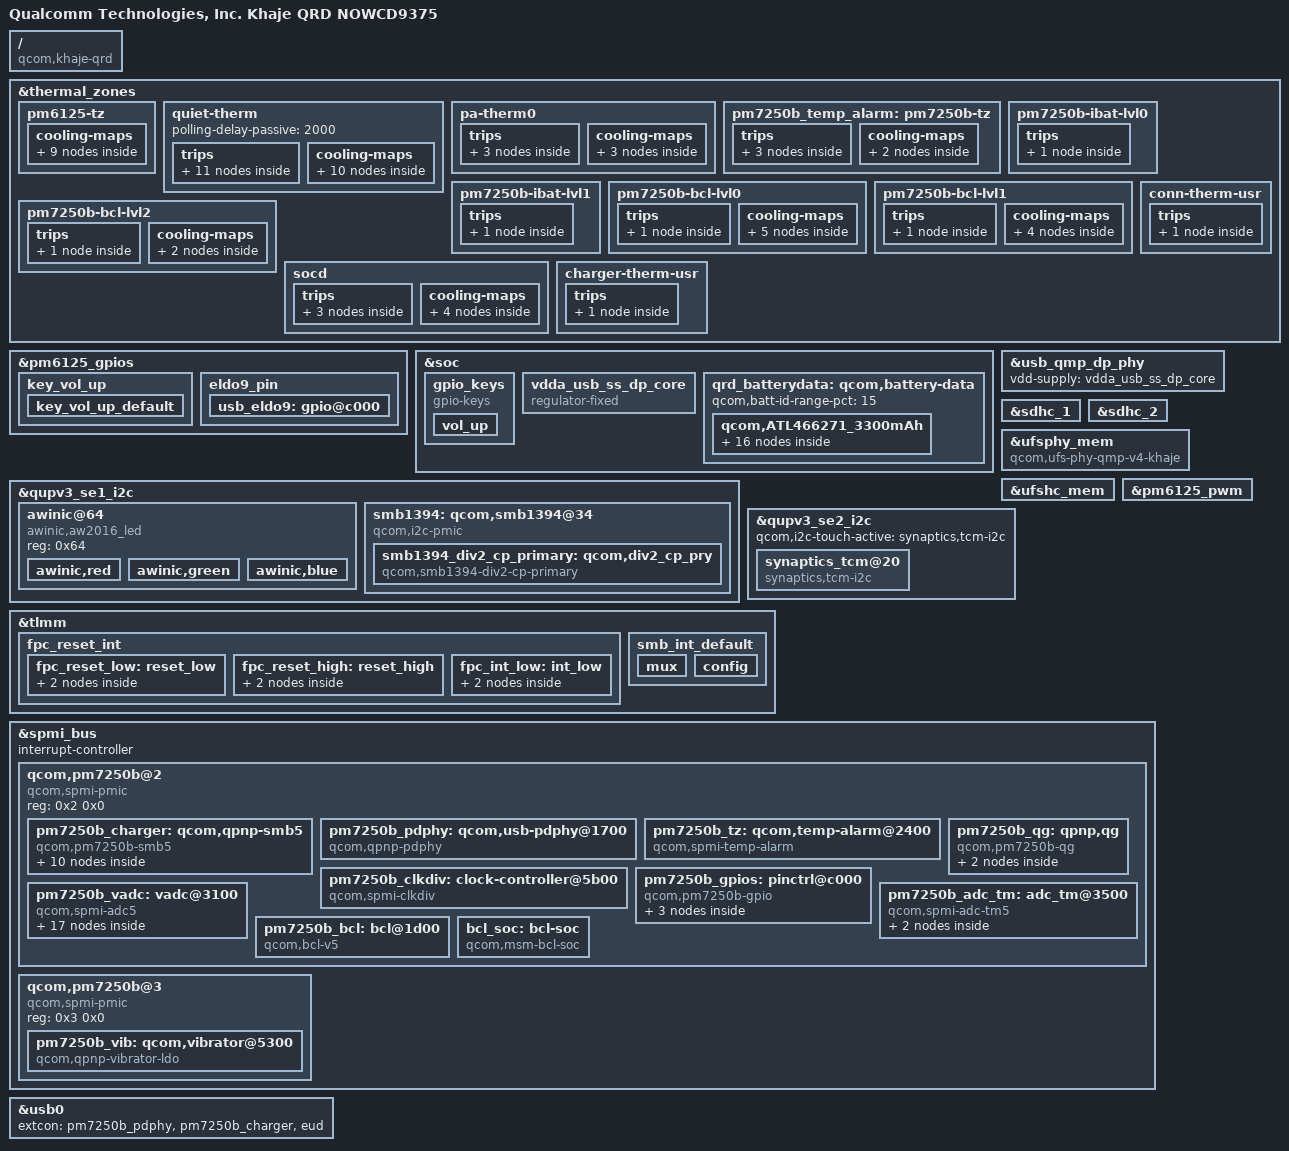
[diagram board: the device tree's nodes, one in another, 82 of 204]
// SPDX-License-Identifier: GPL-2.0-only
/*
 * Stock dtbo.img entry 14: Qualcomm Technologies, Inc. Khaje QRD NOWCD9375
 * Kernel board overlay part, reconstructed from the stock image
 * (Qualcomm reference board as built in the Xiaomi sapphire tree).
 */

/dts-v1/;
/plugin/;

/ {
	model = "Qualcomm Technologies, Inc. Khaje QRD NOWCD9375";
	compatible = "qcom,khaje-qrd", "qcom,khaje", "qcom,qrd";
	qcom,msm-id = <0x24a 0x10000>;
	qcom,board-id = <0x2010b 0x0>;
	qcom,pmic-id = <0x2d 0x2e 0x0 0x0>;
};

#include <dt-bindings/clock/qcom,gcc-khaje.h>
#include <dt-bindings/clock/qcom,rpmcc.h>

&thermal_zones {
	pm6125-tz {
		cooling-maps {
			trip0_cpu0 {
				trip = <&pm6125_trip0>;
				cooling-device = <&CPU0 7 7>;
			};

			trip0_cpu4 {
				trip = <&pm6125_trip0>;
				cooling-device = <&CPU4 6 0xffffffff>;
			};

			trip1_cpu1 {
				trip = <&pm6125_trip1>;
				cooling-device = <&cpu1_pause 1 1>;
			};

			trip1_cpu2 {
				trip = <&pm6125_trip1>;
				cooling-device = <&cpu2_pause 1 1>;
			};

			trip1_cpu3 {
				trip = <&pm6125_trip1>;
				cooling-device = <&cpu3_pause 1 1>;
			};

			trip1_cpu4 {
				trip = <&pm6125_trip1>;
				cooling-device = <&cpu4_pause 1 1>;
			};

			trip1_cpu5 {
				trip = <&pm6125_trip1>;
				cooling-device = <&cpu5_pause 1 1>;
			};

			trip1_cpu6 {
				trip = <&pm6125_trip1>;
				cooling-device = <&cpu6_pause 1 1>;
			};

			trip1_cpu7 {
				trip = <&pm6125_trip1>;
				cooling-device = <&cpu7_pause 1 1>;
			};
		};
	};
};

&pm6125_gpios {
	key_vol_up {
		key_vol_up_default: key_vol_up_default {
			pins = "gpio5";
			function = "normal";
			input-enable;
			bias-pull-up;
			power-source = <0>;
		};
	};

	eldo9_pin {
		usb_eldo9: gpio@c000 {
			pins = "gpio1";
			function = "normal";
			qcom,drive-strength = <2>;
			power-source = <0>;
			bias-disable;
			output-high;
		};
	};
};

&soc {
	gpio_keys {
		compatible = "gpio-keys";
		label = "gpio-keys";
		pinctrl-names = "default";
		pinctrl-0 = <&key_vol_up_default>;

		vol_up {
			label = "volume_up";
			gpios = <&pm6125_gpios 5 1>;
			linux,input-type = <1>;
			linux,code = <115>;
			linux,can-disable;
			debounce-interval = <15>;
			gpio-key,wakeup;
		};
	};

	vdda_usb_ss_dp_core: vdda_usb_ss_dp_core {
		compatible = "regulator-fixed";
		regulator-name = "vdd_supply";
		regulator-min-microvolt = <880000>;
		regulator-max-microvolt = <880000>;
		enable-active-high;
		gpio = <&pm6125_gpios 1 0>;
		pinctrl-names = "default";
		pinctrl-0 = <&usb_eldo9>;
	};
};

&usb_qmp_dp_phy {
	vdd-supply = <&vdda_usb_ss_dp_core>;
};

&qupv3_se1_i2c {
	awinic@64 {
		compatible = "awinic,aw2016_led";
		reg = <0x64>;

		awinic,red {
			awinic,name = "red";
			awinic,id = <0>;
			awinic,imax = <2>;
			awinic,led-current = <3>;
			awinic,max-brightness = <255>;
			awinic,rise-time-ms = <6>;
			awinic,hold-time-ms = <0>;
			awinic,fall-time-ms = <6>;
			awinic,off-time-ms = <4>;
		};

		awinic,green {
			awinic,name = "green";
			awinic,id = <1>;
			awinic,imax = <2>;
			awinic,led-current = <3>;
			awinic,max-brightness = <255>;
			awinic,rise-time-ms = <6>;
			awinic,hold-time-ms = <0>;
			awinic,fall-time-ms = <6>;
			awinic,off-time-ms = <4>;
		};

		awinic,blue {
			awinic,name = "blue";
			awinic,id = <2>;
			awinic,imax = <2>;
			awinic,led-current = <3>;
			awinic,max-brightness = <255>;
			awinic,rise-time-ms = <6>;
			awinic,hold-time-ms = <0>;
			awinic,fall-time-ms = <6>;
			awinic,off-time-ms = <4>;
		};
	};
};

&sdhc_1 {
	vdd-supply = <&L24A>;
	qcom,vdd-voltage-level = <2960000 2960000>;
	qcom,vdd-current-level = <0 570000>;
	vdd-io-supply = <&L11A>;
	qcom,vdd-io-always-on;
	qcom,vdd-io-lpm-sup;
	qcom,vdd-io-voltage-level = <1800000 1800000>;
	qcom,vdd-io-current-level = <0 325000>;
	pinctrl-names = "default", "sleep";
	pinctrl-0 = <&sdc1_on>;
	pinctrl-1 = <&sdc1_off>;
	status = "ok";
};

&sdhc_2 {
	vdd-supply = <&L22A>;
	qcom,vdd-voltage-level = <2960000 2960000>;
	qcom,vdd-current-level = <0 800000>;
	vdd-io-supply = <&L5A>;
	qcom,vdd-io-voltage-level = <1800000 2960000>;
	qcom,vdd-io-current-level = <0 22000>;
	vdd-io-bias-supply = <&L7A>;
	qcom,vdd-io-bias-voltage-level = <1256000 1256000>;
	qcom,vdd-io-bias-current-level = <0 6000>;
	pinctrl-names = "default", "sleep";
	pinctrl-0 = <&sdc2_on>;
	pinctrl-1 = <&sdc2_off>;
	cd-gpios = <&tlmm 88 1>;
	status = "ok";
};

&ufsphy_mem {
	compatible = "qcom,ufs-phy-qmp-v4-khaje";
	vdda-phy-supply = <&L4A>;
	vdda-pll-supply = <&L18A>;
	vdda-phy-max-microamp = <85700>;
	vdda-pll-max-microamp = <18300>;
	status = "ok";
};

&ufshc_mem {
	vdd-hba-supply = <&gcc_ufs_phy_gdsc>;
	vdd-hba-fixed-regulator;
	vcc-supply = <&L24A>;
	vcc-max-microamp = <800000>;
	vccq2-supply = <&L11A>;
	vccq2-max-microamp = <800000>;
	qcom,vddp-ref-clk-supply = <&L18A>;
	qcom,vddp-ref-clk-max-microamp = <100>;
	reset-gpios = <&tlmm 113 1>;
	resets = <&gcc GCC_UFS_PHY_BCR>;
	reset-names = "rst";
	status = "ok";
};

&pm6125_pwm {
	status = "ok";
};

&qupv3_se2_i2c {
	status = "okay";
	qcom,i2c-touch-active = "synaptics,tcm-i2c";

	synaptics_tcm@20 {
		compatible = "synaptics,tcm-i2c";
		reg = <0x20>;
		interrupt-parent = <&tlmm>;
		interrupts = <80 8200>;
		pinctrl-names = "pmx_ts_active", "pmx_ts_suspend", "pmx_ts_release";
		pinctrl-0 = <&ts_int_active &ts_reset_active>;
		pinctrl-1 = <&ts_int_suspend &ts_reset_suspend>;
		pinctrl-2 = <&ts_release>;
		synaptics,irq-gpio = <&tlmm 80 8200>;
		synaptics,irq-on-state = <0>;
		synaptics,reset-gpio = <&tlmm 86 0>;
		synaptics,reset-on-state = <0>;
		synaptics,reset-active-ms = <20>;
		synaptics,reset-delay-ms = <200>;
		synaptics,power-delay-ms = <200>;
		synaptics,ubl-i2c-addr = <0x20>;
		synaptics,extend_report;
		synaptics,firmware-name = "synaptics_firmware_k.img";
	};
};

&thermal_zones {
	quiet-therm {
		polling-delay-passive = <2000>;

		trips {
			quiet_batt_trip0: batt-trip0 {
				temperature = <41000>;
				hysteresis = <2000>;
				type = "passive";
			};

			quiet_modem_trip0: modem-trip0 {
				temperature = <42000>;
				hysteresis = <2000>;
				type = "passive";
			};

			quiet_batt_trip1: batt-trip1 {
				temperature = <43000>;
				hysteresis = <2000>;
				type = "passive";
			};

			quiet_batt_trip2: batt-trip2 {
				temperature = <45000>;
				hysteresis = <2000>;
				type = "passive";
			};

			quiet_gold_trip: gold-trip {
				temperature = <47000>;
				hysteresis = <0>;
				type = "passive";
			};

			quiet_batt_trip3: batt-trip3 {
				temperature = <47000>;
				hysteresis = <2000>;
				type = "passive";
			};

			quiet_batt_trip4: batt-trip4 {
				temperature = <48000>;
				hysteresis = <1000>;
				type = "passive";
			};

			quiet_gpu_trip: gpu-trip {
				temperature = <48000>;
				hysteresis = <4000>;
				type = "passive";
			};

			quiet_silver_trip: silver-trip {
				temperature = <50000>;
				hysteresis = <0>;
				type = "passive";
			};

			quiet_hvx_trip: hvx-trip {
				temperature = <52000>;
				hysteresis = <4000>;
				type = "passive";
			};

			quiet_modem_trip1: modem-trip1 {
				temperature = <60000>;
				hysteresis = <4000>;
				type = "passive";
			};
		};

		cooling-maps {
			gold_cdev {
				trip = <&quiet_gold_trip>;
				cooling-device = <&CPU4 0 4>;
			};

			silver_cdev {
				trip = <&quiet_silver_trip>;
				cooling-device = <&CPU0 0 2>;
			};

			gpu_cdev {
				trip = <&quiet_gpu_trip>;
				cooling-device = <&msm_gpu 0 3>;
			};

			hvx_cdev {
				trip = <&quiet_hvx_trip>;
				cooling-device = <&cdsp_sw 4 4>;
			};

			mdm_cdev0 {
				trip = <&quiet_modem_trip0>;
				cooling-device = <&modem_proc 1 1>;
			};

			mdm_cdev1 {
				trip = <&quiet_modem_trip1>;
				cooling-device = <&modem_proc 3 3>;
			};
		};
	};

	pa-therm0 {
		trips {
			pa_therm0_trip0: pa-therm0-trip0 {
				temperature = <52000>;
				hysteresis = <2000>;
				type = "passive";
			};

			pa_therm0_trip1: pa-therm0-trip1 {
				temperature = <54000>;
				hysteresis = <2000>;
				type = "passive";
			};

			pa_therm0_trip2: pa-therm0-trip2 {
				temperature = <60000>;
				hysteresis = <4000>;
				type = "passive";
			};
		};

		cooling-maps {
			modem_cdev0 {
				trip = <&pa_therm0_trip0>;
				cooling-device = <&modem_pa 1 1>;
			};

			modem_cdev1 {
				trip = <&pa_therm0_trip1>;
				cooling-device = <&modem_pa 2 2>;
			};

			modem_cdev2 {
				trip = <&pa_therm0_trip2>;
				cooling-device = <&modem_pa 3 3>;
			};
		};
	};
};

&tlmm {
	fpc_reset_int: fpc_reset_int {
		fpc_reset_low: reset_low {
			mux {
				pins = "gpio104";
				function = "gpio";
			};

			config {
				pins = "gpio104";
				drive-strength = <2>;
				bias-disable;
				output-low;
			};
		};

		fpc_reset_high: reset_high {
			mux {
				pins = "gpio104";
				function = "gpio";
			};

			config {
				pins = "gpio104";
				drive-strength = <2>;
				bias-disable;
				output-high;
			};
		};

		fpc_int_low: int_low {
			mux {
				pins = "gpio97";
				function = "gpio";
			};

			config {
				pins = "gpio97";
				drive-strength = <2>;
				bias-pull-down;
				input-enable;
			};
		};
	};
};

&spmi_bus {
	#address-cells = <2>;
	#size-cells = <0>;
	interrupt-controller;
	#interrupt-cells = <4>;

	qcom,pm7250b@2 {
		compatible = "qcom,spmi-pmic";
		reg = <0x2 0x0>;
		#address-cells = <1>;
		#size-cells = <0>;

		pm7250b_charger: qcom,qpnp-smb5 {
			compatible = "qcom,pm7250b-smb5";
			depends-on-supply = <&pm7250b_vadc>;
			#address-cells = <1>;
			#size-cells = <1>;
			#cooling-cells = <2>;
			qcom,thermal-mitigation = <8000000 7500000 7000000 6500000 6000000 5500000 5000000 4500000
			                           4000000 3500000 3000000 2500000 2000000 1500000 1000000 500000>;
			qcom,hvdcp2-max-icl-ua = <2000000>;
			qcom,hvdcp2-12v-max-icl-ua = <1500000>;
			status = "ok";
			#io-channel-cells = <1>;
			io-channels = <&pm7250b_vadc 8 &pm7250b_vadc 7
			               &pm7250b_vadc 9 &pm7250b_vadc 6
			               &pm7250b_vadc 79 &pm7250b_vadc 153
			               &pm7250b_vadc 131 &pm7250b_vadc 77
			               &pm7250b_qg 75 &pm7250b_qg 70
			               &pm7250b_qg 69 &pm7250b_qg 66
			               &pm7250b_qg 71 &pm7250b_qg 93
			               &pm7250b_qg 78 &pm7250b_qg 68
			               &pm7250b_qg 91 &pm7250b_qg 72
			               &pm7250b_qg 45 &pm7250b_qg 83
			               &pm7250b_qg 73 &pm7250b_qg 82
			               &pm7250b_qg 84 &pm7250b_qg 86>;
			io-channel-names = "usb_in_voltage", "usb_in_current", "chg_temp", "die_temp", "conn_temp", "sbux_res", "vph_voltage", "skin_temp", "resistance_id", "voltage_now", "temp", "capacity", "voltage_ocv", "voltage_avg", "debug_battery", "real_capacity", "cc_soc", "current_now", "voltage_max", "charge_full", "charge_counter", "cycle_count", "charge_full_design", "time_to_full_now";
			qcom,battery-data = <&qrd_batterydata>;
			qcom,sec-charger-config = <1>;
			qcom,auto-recharge-soc = <98>;
			qcom,step-charging-enable;
			qcom,sw-jeita-enable;
			qcom,charger-temp-max = <800>;
			qcom,smb-temp-max = <800>;
			qcom,suspend-input-on-debug-batt;
			qcom,fcc-stepping-enable;
			qcom,fcc-step-delay-ms = <100>;
			qcom,fcc-step-size-ua = <100000>;
			qcom,smb-internal-pull-kohm = <0>;
			dpdm-supply = <&usb2_phy0>;

			qcom,chgr@1000 {
				reg = <0x1000>;
				interrupts = <2 16 0 1 2 16 1 1
				              2 16 2 1 2 16 3 1
				              2 16 4 1 2 16 5 1
				              2 16 6 1 2 16 7 1>;
				interrupt-names = "chgr-error", "chg-state-change", "step-chg-state-change", "step-chg-soc-update-fail", "step-chg-soc-update-req", "fg-fvcal-qualified", "vph-alarm", "vph-drop-prechg";
			};

			qcom,dcdc@1100 {
				reg = <0x1100>;
				interrupts = <2 17 0 1 2 17 1 1
				              2 17 2 1 2 17 3 3
				              2 17 4 3 2 17 5 3
				              2 17 6 1 2 17 7 3>;
				interrupt-names = "otg-fail", "otg-oc-disable-sw", "otg-oc-hiccup", "bsm-active", "high-duty-cycle", "input-current-limiting", "concurrent-mode-disable", "switcher-power-ok";
			};

			qcom,batif@1200 {
				reg = <0x1200>;
				interrupts = <2 18 0 1 2 18 2 3
				              2 18 3 3 2 18 4 3
				              2 18 5 3 2 18 6 3
				              2 18 7 3>;
				interrupt-names = "bat-temp", "bat-ov", "bat-low", "bat-therm-or-id-missing", "bat-terminal-missing", "buck-oc", "vph-ov";
			};

			qcom,usb@1300 {
				reg = <0x1300>;
				interrupts = <2 19 0 3 2 19 1 3
				              2 19 2 3 2 19 3 3
				              2 19 4 3 2 19 5 3
				              2 19 6 1 2 19 7 1>;
				interrupt-names = "usbin-collapse", "usbin-vashdn", "usbin-uv", "usbin-ov", "usbin-plugin", "usbin-revi-change", "usbin-src-change", "usbin-icl-change";
			};

			qcom,dc@1400 {
				reg = <0x1400>;
				interrupts = <2 20 1 3 2 20 2 3
				              2 20 3 3 2 20 4 3
				              2 20 5 3 2 20 6 1
				              2 20 7 1>;
				interrupt-names = "dcin-vashdn", "dcin-uv", "dcin-ov", "dcin-plugin", "dcin-revi", "dcin-pon", "dcin-en";
			};

			qcom,typec@1500 {
				reg = <0x1500>;
				interrupts = <2 21 0 1 2 21 1 1
				              2 21 2 1 2 21 3 1
				              2 21 4 1 2 21 5 1
				              2 21 6 1 2 21 7 1>;
				interrupt-names = "typec-or-rid-detect-change", "typec-vpd-detect", "typec-cc-state-change", "typec-vconn-oc", "typec-vbus-change", "typec-attach-detach", "typec-legacy-cable-detect", "typec-try-snk-src-detect";
			};

			qcom,misc@1600 {
				reg = <0x1600>;
				interrupts = <2 22 0 1 2 22 1 1
				              2 22 2 1 2 22 3 1
				              2 22 4 3 2 22 5 1
				              2 22 6 1 2 22 7 1>;
				interrupt-names = "wdog-snarl", "wdog-bark", "aicl-fail", "aicl-done", "smb-en", "imp-trigger", "temp-change", "temp-change-smb";
			};

			qcom,chg-sdam@b000 {
				reg = <0xb000>;
			};

			smb5_vbus: qcom,smb5-vbus {
				regulator-name = "smb5-vbus";
			};

			smb5_vconn: qcom,smb5-vconn {
				regulator-name = "smb5-vconn";
			};
		};

		pm7250b_pdphy: qcom,usb-pdphy@1700 {
			compatible = "qcom,qpnp-pdphy";
			reg = <0x1700>;
			interrupts = <2 23 0 1 2 23 1 1
			              2 23 2 1 2 23 3 1
			              2 23 4 1 2 23 5 1
			              2 23 6 1 2 23 7 1>;
			interrupt-names = "sig-tx", "sig-rx", "msg-tx", "msg-rx", "msg-tx-failed", "msg-tx-discarded", "msg-rx-discarded", "fr-swap";
			#io-channel-cells = <1>;
			qcom,default-sink-caps = <5000 3000 9000 3000 12000 2250>;
			vdd-pdphy-supply = <&L15A>;
			vbus-supply = <&smb5_vbus>;
			vconn-supply = <&smb5_vconn>;
			io-channels = <&pm7250b_charger 4 &pm7250b_charger 3
			               &pm7250b_charger 13 &pm7250b_charger 2
			               &pm7250b_charger 31 &pm7250b_charger 29
			               &pm7250b_charger 30 &pm7250b_charger 0
			               &pm7250b_charger 32 &pm7250b_charger 12
			               &pm7250b_charger 11 &pm7250b_charger 10
			               &pm7250b_charger 1 &pm7250b_charger 7>;
			io-channel-names = "pd_active", "typec_cc_orientation", "connector_type", "typec_power_role", "pd_usb_suspend_supported", "typec_src_rp", "pd_in_hard_reset", "pr_current_max", "pr_swap", "pd_voltage_min", "pd_voltage_max", "real_type", "typec_mode", "pe_start";
		};

		pm7250b_tz: qcom,temp-alarm@2400 {
			compatible = "qcom,spmi-temp-alarm";
			reg = <0x2400>;
			interrupts = <2 36 0 3>;
			io-channels = <&pm7250b_vadc 6>;
			io-channel-names = "thermal";
			#thermal-sensor-cells = <0>;
			qcom,temperature-threshold-set = <1>;
		};

		pm7250b_qg: qpnp,qg {
			compatible = "qcom,pm7250b-qg";
			depends-on-supply = <&pm6125_rtc>;
			#address-cells = <1>;
			#size-cells = <1>;
			qcom,vbatt-cutoff-mv = <3400>;
			qcom,vbatt-low-mv = <3500>;
			qcom,vbatt-low-cold-mv = <3800>;
			qcom,vbatt-empty-mv = <3200>;
			qcom,vbatt-empty-cold-mv = <3100>;
			qcom,s3-entry-fifo-length = <2>;
			qcom,soc_decimal_rate = <0 32 10 30 20 28 30 28
			                         40 28 50 28 60 28 70 28
			                         80 28 90 26 95 10 99 5>;
			status = "ok";
			#io-channel-cells = <1>;
			io-channels = <&pm7250b_vadc 42 &pm7250b_vadc 75
			               &pm7250b_charger 55 &pm7250b_charger 63
			               &pm7250b_charger 64 &pm7250b_charger 57>;
			io-channel-names = "batt-therm", "batt-id", "input_current_limited", "recharge_soc", "force_recharge", "charge_done";
			qcom,qg-iterm-ma = <150>;
			qcom,hold-soc-while-full;
			qcom,linearize-soc;
			qcom,cl-feedback-on;
			qcom,tcss-enable;
			qcom,fvss-enable;
			qcom,fvss-vbatt-mv = <3500>;
			qcom,bass-enable;
			qcom,use-cp-iin-sns;

			qcom,qgauge@4800 {
				status = "okay";
				reg = <0x4800>;
				interrupts = <2 72 0 3 2 72 1 3
				              2 72 2 1 2 72 3 1
				              2 72 4 1>;
				interrupt-names = "qg-batt-missing", "qg-vbat-low", "qg-vbat-empty", "qg-fifo-done", "qg-good-ocv";
			};

			qcom,qg-sdam@b100 {
				status = "okay";
				reg = <0xb100>;
			};
		};

		pm7250b_clkdiv: clock-controller@5b00 {
			compatible = "qcom,spmi-clkdiv";
			reg = <0x5b00>;
			#clock-cells = <1>;
			qcom,num-clkdivs = <1>;
			clock-output-names = "pm7250b_div_clk1";
			clocks = <&rpmcc RPM_PXO_CLK>;
			clock-names = "xo";
			assigned-clocks = <&pm7250b_clkdiv 1>;
			assigned-clock-rates = <19200000>;
		};

		pm7250b_gpios: pinctrl@c000 {
			compatible = "qcom,pm7250b-gpio";
			reg = <0xc000>;
			gpio-controller;
			#gpio-cells = <2>;
			interrupt-controller;
			#interrupt-cells = <2>;

			disp_lcd_bias_en {
				disp_lcd_bias_en_default: disp_lcd_bias_en_default {
					pins = "gpio5";
					function = "func1";
					input-disable;
					output-enable;
					bias-disable;
					power-source = <0>;
					qcom,drive-strength = <2>;
				};
			};

			pm7250b_smb_int_default: pm7250b_smb_int_default {
				pins = "gpio6";
				function = "gpio";
				input-enable;
				bias-pull-up;
				qcom,pull-up-strength = <0>;
				power-source = <0>;
			};
		};

		pm7250b_vadc: vadc@3100 {
			compatible = "qcom,spmi-adc5";
			reg = <0x3100>;
			reg-names = "adc5-usr-base";
			#address-cells = <1>;
			#size-cells = <0>;
			interrupts = <2 49 0 1>;
			interrupt-names = "eoc-int-en-set";
			qcom,adc-vdd-reference = <1875>;
			#io-channel-cells = <1>;
			io-channel-ranges;

			ref_gnd@0 {
				reg = <0x0>;
				label = "ref_gnd";
				qcom,pre-scaling = <1 1>;
			};

			vref_1p25@1 {
				reg = <0x1>;
				label = "vref_1p25";
				qcom,pre-scaling = <1 1>;
			};

			die_temp@2 {
				reg = <0x6>;
				label = "die_temp";
				qcom,pre-scaling = <1 1>;
			};

			vph_pwr@83 {
				reg = <0x83>;
				label = "vph_pwr";
				qcom,pre-scaling = <1 3>;
			};

			vbat_sns@84 {
				reg = <0x84>;
				label = "vbat_sns";
				qcom,pre-scaling = <1 3>;
			};

			usb_in_i_uv@7 {
				reg = <0x7>;
				label = "usb_in_i_uv";
				qcom,pre-scaling = <1 1>;
			};

			usb_in_v_div_16@8 {
				reg = <0x8>;
				label = "usb_in_v_div_16";
				qcom,pre-scaling = <1 16>;
			};

			chg_temp@9 {
				reg = <0x9>;
				label = "chg_temp";
				qcom,pre-scaling = <1 1>;
			};

			bat_therm@4a {
				reg = <0x4a>;
				label = "bat_therm";
				qcom,ratiometric;
				qcom,hw-settle-time = <200>;
				qcom,pre-scaling = <1 1>;
			};

			bat_therm_30k@2a {
				reg = <0x2a>;
				label = "bat_therm_30k";
				qcom,ratiometric;
				qcom,hw-settle-time = <200>;
				qcom,pre-scaling = <1 1>;
			};

			bat_therm_400k@6a {
				reg = <0x6a>;
				label = "bat_therm_400k";
				qcom,ratiometric;
				qcom,hw-settle-time = <200>;
				qcom,pre-scaling = <1 1>;
			};

			bat_id@4b {
				reg = <0x4b>;
				label = "bat_id";
				qcom,ratiometric;
				qcom,hw-settle-time = <200>;
				qcom,pre-scaling = <1 1>;
			};

			smb1390_therm@e {
				reg = <0xe>;
				label = "smb1390_therm";
				qcom,hw-settle-time = <200>;
				qcom,pre-scaling = <1 1>;
				qcom,scale-fn-type = <16>;
			};

			chg_sbux@99 {
				reg = <0x99>;
				label = "chg_sbux";
				qcom,pre-scaling = <1 3>;
			};

			mid_chg_div6@1e {
				reg = <0x1e>;
				label = "chg_mid";
				qcom,pre-scaling = <1 6>;
			};

			charger_skin_therm@4d {
				reg = <0x4d>;
				label = "charger_skin_therm";
				qcom,ratiometric;
				qcom,hw-settle-time = <200>;
				qcom,pre-scaling = <1 1>;
			};

			conn_therm@4f {
				reg = <0x4f>;
				label = "conn_therm";
				qcom,ratiometric;
				qcom,hw-settle-time = <200>;
				qcom,pre-scaling = <1 1>;
			};
		};

		pm7250b_adc_tm: adc_tm@3500 {
			compatible = "qcom,spmi-adc-tm5";
			reg = <0x3500>;
			interrupts = <2 53 0 1>;
			interrupt-names = "pm-adc-tm5";
			#address-cells = <1>;
			#size-cells = <0>;
			#thermal-sensor-cells = <1>;
			status = "ok";

			charger_skin_therm@4d {
				reg = <0x0>;
				io-channels = <&pm7250b_vadc 77>;
				qcom,ratiometric;
				qcom,hw-settle-time-us = <200>;
			};

			conn_therm@4f {
				reg = <0x1>;
				io-channels = <&pm7250b_vadc 79>;
				qcom,ratiometric;
				qcom,hw-settle-time-us = <200>;
			};
		};

		pm7250b_bcl: bcl@1d00 {
			compatible = "qcom,bcl-v5";
			reg = <0x1d00>;
			interrupts = <2 29 0 0 2 29
			              1 0 2 29 2 0>;
			interrupt-names = "bcl-lvl0", "bcl-lvl1", "bcl-lvl2";
			#thermal-sensor-cells = <1>;
		};

		bcl_soc: bcl-soc {
			compatible = "qcom,msm-bcl-soc";
			#thermal-sensor-cells = <0>;
		};
	};

	qcom,pm7250b@3 {
		compatible = "qcom,spmi-pmic";
		reg = <0x3 0x0>;
		#address-cells = <1>;
		#size-cells = <0>;

		pm7250b_vib: qcom,vibrator@5300 {
			compatible = "qcom,qpnp-vibrator-ldo";
			reg = <0x5300>;
			qcom,vib-ldo-volt-uv = <3000000>;
			qcom,disable-overdrive;
		};
	};
};

&thermal_zones {
	pm7250b_temp_alarm: pm7250b-tz {
		polling-delay-passive = <100>;
		polling-delay = <0>;
		thermal-sensors = <&pm7250b_tz>;

		trips {
			pm7250b_trip0: trip0 {
				temperature = <95000>;
				hysteresis = <0>;
				type = "passive";
			};

			pm7250b_trip1: trip1 {
				temperature = <115000>;
				hysteresis = <0>;
				type = "passive";
			};

			trip2 {
				temperature = <145000>;
				hysteresis = <0>;
				type = "passive";
			};
		};
	};

	pm7250b-ibat-lvl0 {
		polling-delay-passive = <0>;
		polling-delay = <0>;
		thermal-sensors = <&pm7250b_bcl 0>;

		trips {
			ibat_lvl0: ibat-lvl0 {
				temperature = <5500>;
				hysteresis = <200>;
				type = "passive";
			};
		};
	};

	pm7250b-ibat-lvl1 {
		polling-delay-passive = <0>;
		polling-delay = <0>;
		thermal-sensors = <&pm7250b_bcl 1>;

		trips {
			ibat_lvl1: ibat-lvl1 {
				temperature = <6000>;
				hysteresis = <200>;
				type = "passive";
			};
		};
	};

	pm7250b-bcl-lvl0 {
		polling-delay-passive = <100>;
		polling-delay = <0>;
		thermal-sensors = <&pm7250b_bcl 5>;

		trips {
			b_bcl_lvl0: b-bcl-lvl0 {
				temperature = <1>;
				hysteresis = <1>;
				type = "passive";
			};
		};
	};

	pm7250b-bcl-lvl1 {
		polling-delay-passive = <100>;
		polling-delay = <0>;
		thermal-sensors = <&pm7250b_bcl 6>;

		trips {
			b_bcl_lvl1: b-bcl-lvl1 {
				temperature = <1>;
				hysteresis = <1>;
				type = "passive";
			};
		};
	};

	pm7250b-bcl-lvl2 {
		polling-delay-passive = <100>;
		polling-delay = <0>;
		thermal-sensors = <&pm7250b_bcl 7>;

		trips {
			b_bcl_lvl2: b-bcl-lvl2 {
				temperature = <1>;
				hysteresis = <1>;
				type = "passive";
			};
		};
	};

	socd {
		polling-delay-passive = <100>;
		polling-delay = <0>;

		trips {
			thermal-engine-trip {
				temperature = <100>;
				hysteresis = <0>;
				type = "passive";
			};

			thermal-hal-trip {
				temperature = <100>;
				hysteresis = <0>;
				type = "passive";
			};

			soc_trip: soc-trip {
				temperature = <90>;
				hysteresis = <0>;
				type = "passive";
			};
		};
	};
};

&thermal_zones {
	charger-therm-usr {
		polling-delay-passive = <0>;
		polling-delay = <0>;
		thermal-governor = "user_space";
		thermal-sensors = <&pm7250b_adc_tm 0>;
		wake-capable-sensor;

		trips {
			active-config0 {
				temperature = <125000>;
				hysteresis = <1000>;
				type = "passive";
			};
		};
	};

	conn-therm-usr {
		polling-delay-passive = <0>;
		polling-delay = <0>;
		thermal-governor = "user_space";
		thermal-sensors = <&pm7250b_adc_tm 1>;
		wake-capable-sensor;

		trips {
			active-config0 {
				temperature = <125000>;
				hysteresis = <1000>;
				type = "passive";
			};
		};
	};
};

&thermal_zones {
	pm7250b-tz {
		cooling-maps {
			trip0_bat {
				trip = <&pm7250b_trip0>;
				cooling-device = <&pm7250b_charger 9 9>;
			};

			trip1_bat {
				trip = <&pm7250b_trip1>;
				cooling-device = <&pm7250b_charger 10 10>;
			};
		};
	};

	socd {
		cooling-maps {
			soc_cpu4 {
				trip = <&soc_trip>;
				cooling-device = <&cpu4_pause 1 1>;
			};

			soc_cpu5 {
				trip = <&soc_trip>;
				cooling-device = <&cpu5_pause 1 1>;
			};

			soc_cpu6 {
				trip = <&soc_trip>;
				cooling-device = <&cpu6_pause 1 1>;
			};

			soc_cpu7 {
				trip = <&soc_trip>;
				cooling-device = <&cpu7_pause 1 1>;
			};
		};
	};

	pm7250b-bcl-lvl0 {
		cooling-maps {
			lbat0_cpufreq4 {
				trip = <&b_bcl_lvl0>;
				cooling-device = <&CPU4 2 2>;
			};

			lbat0_cpu6 {
				trip = <&b_bcl_lvl0>;
				cooling-device = <&cpu6_pause 1 1>;
			};

			lbat0_cpu7 {
				trip = <&b_bcl_lvl0>;
				cooling-device = <&cpu7_pause 1 1>;
			};

			lbat0_gpu {
				trip = <&b_bcl_lvl0>;
				cooling-device = <&msm_gpu 2 2>;
			};

			lbat0_cdsp {
				trip = <&b_bcl_lvl0>;
				cooling-device = <&cdsp_sw 2 2>;
			};
		};
	};

	pm7250b-bcl-lvl1 {
		cooling-maps {
			lbat1_cpu4 {
				trip = <&b_bcl_lvl1>;
				cooling-device = <&cpu4_pause 1 1>;
			};

			lbat1_cpu5 {
				trip = <&b_bcl_lvl1>;
				cooling-device = <&cpu5_pause 1 1>;
			};

			lbat1_gpu {
				trip = <&b_bcl_lvl1>;
				cooling-device = <&msm_gpu 4 4>;
			};

			lbat1_cdsp {
				trip = <&b_bcl_lvl1>;
				cooling-device = <&cdsp_sw 4 4>;
			};
		};
	};

	pm7250b-bcl-lvl2 {
		cooling-maps {
			lbat2_gpu {
				trip = <&b_bcl_lvl2>;
				cooling-device = <&msm_gpu 4 0xffffffff>;
			};

			lbat2_cdsp {
				trip = <&b_bcl_lvl2>;
				cooling-device = <&cdsp_sw 4 4>;
			};
		};
	};
};

&soc {
	qrd_batterydata: qcom,battery-data {
		qcom,batt-id-range-pct = <15>;

		qcom,ATL466271_3300mAh {
			qcom,max-voltage-uv = <4400000>;
			qcom,fg-cc-cv-threshold-uv = <4390000>;
			qcom,fastchg-current-ma = <8000>;
			qcom,batt-id-kohm = <24>;
			qcom,battery-beta = <4250>;
			qcom,battery-therm-kohm = <100>;
			qcom,battery-type = "ATL466271_3300mAh_averaged_MasterSlave_Jun12th2019";
			qcom,qg-batt-profile-ver = <100>;
			qcom,jeita-fcc-ranges = <0 100 1600000 101 200 3200000 201 450
			                         8000000 451 550 1600000>;
			qcom,jeita-fv-ranges = <0 100 4400000 101 200 4400000 201 450
			                        4400000 451 550 4050000>;
			qcom,step-chg-ranges = <3500000 4000000 8000000 4000001 4200000 6000000 4200001 4400000
			                        4000000>;
			qcom,ocv-based-step-chg;
			qcom,jeita-soft-thresholds = <19660 8376>;
			qcom,jeita-hard-thresholds = <22733 6173>;
			qcom,jeita-soft-hys-thresholds = <18644 9152>;
			qcom,jeita-soft-fcc-ua = <1600000 1600000>;
			qcom,jeita-soft-fv-uv = <4400000 4050000>;

			qcom,fcc1-temp-lut {
				qcom,lut-col-legend = <0 10 25 40 50>;
				qcom,lut-data = [00 00 0c 77 00 00 0c bc 00 00 0c f8 00 00 0d 1a 00 00 0d 26];
			};

			qcom,fcc2-temp-lut {
				qcom,lut-col-legend = <0xfffffff6 0 10 25 40 50>;
				qcom,lut-data = [00 00 0c eb 00 00 0c ed 00 00 0c fc 00 00 0d 04 00 00 0d 02 00 00 0c fe];
			};

			qcom,pc-temp-v1-lut {
				qcom,lut-col-legend = <0 10 25 40 50>;
				qcom,lut-row-legend = <10000 9800 9600 9400 9200 9000 8800 8600
				                       8400 8200 8000 7800 7600 7400 7200 7000
				                       6800 6600 6400 6200 6000 5800 5600 5400
				                       5200 5000 4800 4600 4400 4200 4000 3800
				                       3600 3400 3200 3000 2800 2600 2400 2200
				                       2000 1800 1600 1400 1200 1000 900 800
				                       700 600 500 400 300 200 100 0>;
				qcom,lut-data = [00 00 aa be 00 00 ab 31 00 00 ab 85 00 00 ab a1 00 00 ab a6 00 00 a9 d1 00 00 aa 55 00 00 aa ba 00 00 aa c9 00 00 aa cb 00 00 a8 e5 00 00 a9 74 00 00 a9 e1 00 00 a9 f5 00 00 a9 f6 00 00 a7 fb 00 00 a8 8e 00 00 a9 03 00 00 a9 1e 00 00 a9 23 00 00 a7 17 00 00 a7 a6 00 00 a8 1e 00 00 a8 3e 00 00 a8 47 00 00 a6 36 00 00 a6 bf 00 00 a7 34 00 00 a7 55 00 00 a7 62 00 00 a5 58 00 00 a5 d9 00 00 a6 4d 00 00 a6 6e 00 00 a6 7c 00 00 a4 7d 00 00 a4 f6 00 00 a5 65 00 00 a5 87 00 00 a5 96 00 00 a3 a6 00 00 a4 18 00 00 a4 81 00 00 a4 a1 00 00 a4 b1 00 00 a2 d4 00 00 a3 3d 00 00 a3 9e 00 00 a3 bd 00 00 a3 cd 00 00 a2 04 00 00 a2 66 00 00 a2 bf 00 00 a2 da 00 00 a2 e9 00 00 a1 3e 00 00 a1 90 00 00 a1 e6 00 00 a1 fb 00 00 a2 09 00 00 a0 8f 00 00 a0 c7 00 00 a1 10 00 00 a1 1f 00 00 a1 2d 00 00 9f ef 00 00 a0 1b 00 00 a0 43 00 00 a0 4b 00 00 a0 57 00 00 9f 34 00 00 9f 77 00 00 9f 7f 00 00 9f 81 00 00 9f 88 00 00 9e 33 00 00 9e b1 00 00 9e be 00 00 9e bf 00 00 9e c2 00 00 9d 2b 00 00 9d b3 00 00 9d f2 00 00 9d fa 00 00 9e 00 00 00 9c 6f 00 00 9c c8 00 00 9d 20 00 00 9d 31 00 00 9d 43 00 00 9b e1 00 00 9c 2a 00 00 9c 67 00 00 9c 75 00 00 9c 8c 00 00 9b 5a 00 00 9b a5 00 00 9b d5 00 00 9b d6 00 00 9b e5 00 00 9a d5 00 00 9a f4 00 00 9b 3e 00 00 9b 3e 00 00 9b 44 00 00 9a 4a 00 00 99 ea 00 00 9a 67 00 00 9a 7a 00 00 9a 82 00 00 99 97 00 00 98 f7 00 00 99 5c 00 00 99 76 00 00 99 83 00 00 98 91 00 00 98 6a 00 00 98 90 00 00 98 96 00 00 98 9e 00 00 97 b9 00 00 98 02 00 00 98 04 00 00 97 fd 00 00 98 01 00 00 97 5c 00 00 97 9e 00 00 97 8e 00 00 97 7f 00 00 97 82 00 00 97 20 00 00 97 3a 00 00 97 1e 00 00 97 0c 00 00 97 0b 00 00 96 e4 00 00 96 dd 00 00 96 b8 00 00 96 a6 00 00 96 9f 00 00 96 a6 00 00 96 88 00 00 96 5b 00 00 96 47 00 00 96 3c 00 00 96 68 00 00 96 3b 00 00 96 06 00 00 95 ec 00 00 95 df 00 00 96 2d 00 00 95 f7 00 00 95 ba 00 00 95 99 00 00 95 8a 00 00 95 f4 00 00 95 ba 00 00 95 75 00 00 95 4f 00 00 95 3d 00 00 95 c1 00 00 95 84 00 00 95 37 00 00 95 0c 00 00 94 f6 00 00 95 94 00 00 95 54 00 00 94 ff 00 00 94 cf 00 00 94 b4 00 00 95 6b 00 00 95 2b 00 00 94 cf 00 00 94 9b 00 00 94 79 00 00 95 46 00 00 95 02 00 00 94 a1 00 00 94 68 00 00 94 3f 00 00 95 26 00 00 94 df 00 00 94 74 00 00 94 2d 00 00 93 f9 00 00 94 ff 00 00 94 b7 00 00 94 46 00 00 93 ed 00 00 93 a8 00 00 94 ba 00 00 94 76 00 00 94 07 00 00 93 a1 00 00 93 4f 00 00 94 56 00 00 94 0f 00 00 93 aa 00 00 93 41 00 00 92 ee 00 00 93 e8 00 00 93 9c 00 00 93 3c 00 00 92 d3 00 00 92 82 00 00 93 68 00 00 93 1f 00 00 92 c3 00 00 92 51 00 00 92 00 00 00 92 d8 00 00 92 92 00 00 92 39 00 00 91 be 00 00 91 6c 00 00 92 33 00 00 91 e7 00 00 91 96 00 00 91 20 00 00 90 cf 00 00 91 ad 00 00 91 62 00 00 91 0f 00 00 90 ad 00 00 90 64 00 00 91 62 00 00 91 1c 00 00 90 c5 00 00 90 70 00 00 90 36 00 00 91 4d 00 00 91 07 00 00 90 b3 00 00 90 5e 00 00 90 23 00 00 91 38 00 00 90 fa 00 00 90 a3 00 00 90 51 00 00 90 14 00 00 91 20 00 00 90 de 00 00 90 8d 00 00 90 33 00 00 8f ed 00 00 90 bd 00 00 90 5a 00 00 90 0f 00 00 8f 73 00 00 8f 0f 00 00 8f 42 00 00 8e e2 00 00 8e ae 00 00 8d fb 00 00 8d 92 00 00 8d 63 00 00 8c f6 00 00 8c c9 00 00 8c 13 00 00 8b a7 00 00 8a f6 00 00 8a 79 00 00 8a 63 00 00 89 9d 00 00 89 2c 00 00 87 a9 00 00 87 0e 00 00 87 0e 00 00 86 3a 00 00 85 c2 00 00 82 79 00 00 81 94 00 00 81 c9 00 00 80 dd 00 00 80 53 00 00 75 30 00 00 75 30 00 00 75 30 00 00 75 30 00 00 75 30];
			};

			qcom,pc-temp-v2-lut {
				qcom,lut-col-legend = <0xfffffff6 0 10 25 40 50>;
				qcom,lut-row-legend = <10000 9800 9600 9400 9200 9000 8800 8600
				                       8400 8200 8000 7800 7600 7400 7200 7000
				                       6800 6600 6400 6200 6000 5800 5600 5400
				                       5200 5000 4800 4600 4400 4200 4000 3800
				                       3600 3400 3200 3000 2800 2600 2400 2200
				                       2000 1800 1600 1400 1200 1000 900 800
				                       700 600 500 400 300 200 100 0>;
				qcom,lut-data = [00 00 ab c7 00 00 ab ae 00 00 ab 9a 00 00 ab 81 00 00 ab 4f 00 00 ab 3b 00 00 aa 5e 00 00 aa 7f 00 00 aa 93 00 00 aa 8f 00 00 aa 61 00 00 aa 4c 00 00 a9 0f 00 00 a9 61 00 00 a9 92 00 00 a9 a0 00 00 a9 77 00 00 a9 62 00 00 a7 dc 00 00 a8 54 00 00 a8 9a 00 00 a8 b4 00 00 a8 8e 00 00 a8 7a 00 00 a6 c0 00 00 a7 59 00 00 a7 a9 00 00 a7 cc 00 00 a7 a9 00 00 a7 97 00 00 a5 c0 00 00 a6 64 00 00 a6 ba 00 00 a6 e4 00 00 a6 c3 00 00 a6 b3 00 00 a4 ec 00 00 a5 6e 00 00 a5 ce 00 00 a5 fa 00 00 a5 da 00 00 a5 cb 00 00 a4 24 00 00 a4 7e 00 00 a4 e4 00 00 a5 11 00 00 a4 f1 00 00 a4 e2 00 00 a3 2c 00 00 a3 99 00 00 a3 fe 00 00 a4 2b 00 00 a4 0b 00 00 a3 fc 00 00 a1 f2 00 00 a2 be 00 00 a3 1b 00 00 a3 47 00 00 a3 26 00 00 a3 17 00 00 a1 13 00 00 a1 e8 00 00 a2 3b 00 00 a2 66 00 00 a2 45 00 00 a2 36 00 00 a0 c1 00 00 a1 13 00 00 a1 5e 00 00 a1 88 00 00 a1 66 00 00 a1 59 00 00 a0 80 00 00 a0 42 00 00 a0 86 00 00 a0 ae 00 00 a0 8c 00 00 a0 7f 00 00 9f c8 00 00 9f 80 00 00 9f c3 00 00 9f e2 00 00 9f bd 00 00 9f ad 00 00 9d ff 00 00 9e cd 00 00 9f 10 00 00 9f 20 00 00 9e f6 00 00 9e e0 00 00 9c 62 00 00 9e 0a 00 00 9e 4d 00 00 9e 59 00 00 9e 2f 00 00 9e 18 00 00 9b 6c 00 00 9d 1d 00 00 9d 64 00 00 9d 7f 00 00 9d 60 00 00 9d 55 00 00 9a a1 00 00 9c 1f 00 00 9c 72 00 00 9c aa 00 00 9c 97 00 00 9c 98 00 00 99 ee 00 00 9b 36 00 00 9b a1 00 00 9b f6 00 00 9b e8 00 00 9b e9 00 00 99 50 00 00 9a 5b 00 00 9a e4 00 00 9b 57 00 00 9b 4a 00 00 9b 46 00 00 98 a2 00 00 99 89 00 00 9a 20 00 00 9a 9f 00 00 9a 94 00 00 9a 8e 00 00 97 b0 00 00 98 bc 00 00 99 40 00 00 99 a8 00 00 99 a0 00 00 99 9b 00 00 96 b8 00 00 97 fc 00 00 98 69 00 00 98 b1 00 00 98 aa 00 00 98 a8 00 00 96 1a 00 00 97 5b 00 00 97 bd 00 00 97 fa 00 00 97 f7 00 00 97 f5 00 00 95 a6 00 00 96 d1 00 00 97 2b 00 00 97 60 00 00 97 63 00 00 97 62 00 00 95 52 00 00 96 4d 00 00 96 aa 00 00 96 dd 00 00 96 e3 00 00 96 e1 00 00 95 14 00 00 95 bf 00 00 96 35 00 00 96 6a 00 00 96 71 00 00 96 6f 00 00 94 e1 00 00 95 3c 00 00 95 cc 00 00 96 03 00 00 96 0a 00 00 96 07 00 00 94 ae 00 00 94 e0 00 00 95 6d 00 00 95 a4 00 00 95 aa 00 00 95 a7 00 00 94 7e 00 00 94 9b 00 00 95 16 00 00 95 4d 00 00 95 50 00 00 95 4c 00 00 94 50 00 00 94 64 00 00 94 c2 00 00 94 fc 00 00 94 fe 00 00 94 f9 00 00 94 25 00 00 94 36 00 00 94 6c 00 00 94 b0 00 00 94 b3 00 00 94 ae 00 00 93 fa 00 00 94 0d 00 00 94 21 00 00 94 69 00 00 94 6b 00 00 94 65 00 00 93 cc 00 00 93 e5 00 00 93 ee 00 00 94 25 00 00 94 26 00 00 94 1a 00 00 93 9d 00 00 93 bf 00 00 93 c7 00 00 93 e3 00 00 93 e2 00 00 93 cd 00 00 93 6b 00 00 93 95 00 00 93 9e 00 00 93 9d 00 00 93 8f 00 00 93 71 00 00 93 38 00 00 93 67 00 00 93 73 00 00 93 53 00 00 93 24 00 00 92 f9 00 00 92 ff 00 00 93 32 00 00 93 42 00 00 93 05 00 00 92 b7 00 00 92 81 00 00 92 ba 00 00 92 f3 00 00 93 00 00 00 92 b7 00 00 92 5d 00 00 92 22 00 00 92 68 00 00 92 a6 00 00 92 ab 00 00 92 65 00 00 92 0a 00 00 91 cd 00 00 92 09 00 00 92 49 00 00 92 47 00 00 92 06 00 00 91 aa 00 00 91 6c 00 00 91 94 00 00 91 c9 00 00 91 ca 00 00 91 95 00 00 91 3a 00 00 90 f9 00 00 91 18 00 00 91 39 00 00 91 3d 00 00 91 0f 00 00 90 b5 00 00 90 73 00 00 90 a3 00 00 90 a2 00 00 90 a1 00 00 90 7b 00 00 90 1f 00 00 8f de 00 00 90 44 00 00 90 36 00 00 90 4b 00 00 90 2c 00 00 8f e9 00 00 8f b0 00 00 8f f7 00 00 8f f9 00 00 90 23 00 00 90 15 00 00 8f d2 00 00 8f 9a 00 00 8f cc 00 00 8f db 00 00 90 0b 00 00 90 03 00 00 8f c1 00 00 8f 8d 00 00 8f 99 00 00 8f b2 00 00 8f ee 00 00 8f eb 00 00 8f ab 00 00 8f 72 00 00 8f 47 00 00 8f 71 00 00 8f a7 00 00 8f ab 00 00 8f 54 00 00 8e f5 00 00 8e 7b 00 00 8e c7 00 00 8e c2 00 00 8e c8 00 00 8e 26 00 00 8d a8 00 00 8c e2 00 00 8d 4d 00 00 8d 1f 00 00 8d 25 00 00 8c 61 00 00 8b d5 00 00 8a ab 00 00 8b 3f 00 00 8a fb 00 00 8b 0c 00 00 8a 2a 00 00 89 8b 00 00 87 ce 00 00 88 98 00 00 88 2f 00 00 88 5d 00 00 87 49 00 00 86 95 00 00 83 f8 00 00 84 e8 00 00 84 8f 00 00 84 cc 00 00 83 7a 00 00 82 80 00 00 7e 9c 00 00 7f c7 00 00 7f 37 00 00 7f 8a 00 00 7c 60 00 00 7a 4f 00 00 6e 37 00 00 70 9f 00 00 6b 82 00 00 6f a3 00 00 6c a6 00 00 6b 7e];
			};

			qcom,pc-temp-z1-lut {
				qcom,lut-col-legend = <0 10 25 40 50>;
				qcom,lut-row-legend = <10000 9800 9600 9400 9200 9000 8800 8600
				                       8400 8200 8000 7800 7600 7400 7200 7000
				                       6800 6600 6400 6200 6000 5800 5600 5400
				                       5200 5000 4800 4600 4400 4200 4000 3800
				                       3600 3400 3200 3000 2800 2600 2400 2200
				                       2000 1800 1600 1400 1200 1000 900 800
				                       700 600 500 400 300 200 100 0>;
				qcom,lut-data = [00 00 2d fa 00 00 2b 9f 00 00 29 0c 00 00 27 d8 00 00 27 8b 00 00 2e 1a 00 00 2b b9 00 00 29 53 00 00 28 21 00 00 27 ce 00 00 2e 1e 00 00 2b c0 00 00 29 55 00 00 28 23 00 00 27 cf 00 00 2e 1d 00 00 2b af 00 00 29 4a 00 00 28 23 00 00 27 cf 00 00 2e 10 00 00 2b a2 00 00 29 3d 00 00 28 1e 00 00 27 cd 00 00 2e 01 00 00 2b 92 00 00 29 31 00 00 28 18 00 00 27 c9 00 00 2d f5 00 00 2b 7b 00 00 29 29 00 00 28 13 00 00 27 c6 00 00 2d eb 00 00 2b 6c 00 00 29 22 00 00 28 0f 00 00 27 c4 00 00 2d df 00 00 2b 67 00 00 29 1c 00 00 28 0b 00 00 27 c2 00 00 2d d7 00 00 2b 64 00 00 29 18 00 00 28 0a 00 00 27 c1 00 00 2d d2 00 00 2b 64 00 00 29 15 00 00 28 09 00 00 27 bf 00 00 2d ce 00 00 2b 64 00 00 29 12 00 00 28 08 00 00 27 be 00 00 2d c9 00 00 2b 64 00 00 29 10 00 00 28 08 00 00 27 bd 00 00 2d c5 00 00 2b 61 00 00 29 0f 00 00 28 07 00 00 27 bd 00 00 2d c2 00 00 2b 5b 00 00 29 0e 00 00 28 07 00 00 27 bc 00 00 2d b8 00 00 2b 59 00 00 29 0c 00 00 28 05 00 00 27 bc 00 00 2d ad 00 00 2b 57 00 00 29 0b 00 00 28 05 00 00 27 bc 00 00 2d ad 00 00 2b 57 00 00 29 0a 00 00 28 05 00 00 27 bc 00 00 2d b8 00 00 2b 59 00 00 29 0a 00 00 28 06 00 00 27 be 00 00 2d c2 00 00 2b 5d 00 00 29 0d 00 00 28 08 00 00 27 bf 00 00 2d ce 00 00 2b 62 00 00 29 11 00 00 28 0c 00 00 27 c1 00 00 2d dd 00 00 2b 6a 00 00 29 15 00 00 28 0e 00 00 27 c3 00 00 2d e0 00 00 2b 72 00 00 29 1a 00 00 28 10 00 00 27 c5 00 00 2d d9 00 00 2b 78 00 00 29 1f 00 00 28 12 00 00 27 c7 00 00 2d d4 00 00 2b 7d 00 00 29 24 00 00 28 14 00 00 27 c9 00 00 2d d5 00 00 2b 7e 00 00 29 29 00 00 28 18 00 00 27 cb 00 00 2d d9 00 00 2b 7c 00 00 29 2e 00 00 28 1b 00 00 27 ce 00 00 2d dc 00 00 2b 7b 00 00 29 34 00 00 28 20 00 00 27 d2 00 00 2d df 00 00 2b 7d 00 00 29 39 00 00 28 24 00 00 27 d5 00 00 2d e3 00 00 2b 81 00 00 29 3e 00 00 28 28 00 00 27 d8 00 00 2d e6 00 00 2b 86 00 00 29 44 00 00 28 2d 00 00 27 db 00 00 2d ea 00 00 2b 92 00 00 29 4b 00 00 28 30 00 00 27 de 00 00 2d ee 00 00 2b 9d 00 00 29 53 00 00 28 34 00 00 27 e1 00 00 2d f9 00 00 2b 9d 00 00 29 58 00 00 28 38 00 00 27 e5 00 00 2e 05 00 00 2b 99 00 00 29 5d 00 00 28 3d 00 00 27 e9 00 00 2e 0d 00 00 2b 97 00 00 29 62 00 00 28 42 00 00 27 ed 00 00 2e 14 00 00 2b a1 00 00 29 68 00 00 28 48 00 00 27 f1 00 00 2e 1b 00 00 2b ae 00 00 29 6e 00 00 28 4d 00 00 27 f5 00 00 2e 21 00 00 2b b1 00 00 29 74 00 00 28 52 00 00 27 f9 00 00 2e 28 00 00 2b b2 00 00 29 7b 00 00 28 56 00 00 27 fc 00 00 2e 2b 00 00 2b b4 00 00 29 81 00 00 28 5a 00 00 27 ff 00 00 2e 2d 00 00 2b bf 00 00 29 86 00 00 28 5f 00 00 28 03 00 00 2e 2f 00 00 2b c8 00 00 29 8c 00 00 28 64 00 00 28 06 00 00 2e 32 00 00 2b c6 00 00 29 92 00 00 28 66 00 00 28 08 00 00 2e 2c 00 00 2b cf 00 00 29 98 00 00 28 68 00 00 28 09 00 00 2e 2c 00 00 2b d4 00 00 29 9f 00 00 28 6b 00 00 28 0a 00 00 2e 36 00 00 2b d9 00 00 29 a4 00 00 28 6c 00 00 28 0c 00 00 2e 28 00 00 2b e0 00 00 29 a2 00 00 28 6e 00 00 28 0d 00 00 2e 37 00 00 2b d8 00 00 29 a6 00 00 28 72 00 00 28 11 00 00 2e 50 00 00 2b d5 00 00 29 af 00 00 28 76 00 00 28 15 00 00 2e 39 00 00 2b e1 00 00 29 b1 00 00 28 7a 00 00 28 19 00 00 2e 48 00 00 2b f3 00 00 29 b6 00 00 28 80 00 00 28 1e 00 00 2e 6d 00 00 2b f9 00 00 29 c0 00 00 28 86 00 00 28 23 00 00 2e 7a 00 00 2c 18 00 00 29 ce 00 00 28 8e 00 00 28 2a 00 00 2e 7a 00 00 2c 18 00 00 29 ce 00 00 28 8e 00 00 28 2a 00 00 2e 7a 00 00 2c 18 00 00 29 ce 00 00 28 8e 00 00 28 2a];
			};

			qcom,pc-temp-z2-lut {
				qcom,lut-col-legend = <0 10 25 40 50>;
				qcom,lut-row-legend = <10000 9800 9600 9400 9200 9000 8800 8600
				                       8400 8200 8000 7800 7600 7400 7200 7000
				                       6800 6600 6400 6200 6000 5800 5600 5400
				                       5200 5000 4800 4600 4400 4200 4000 3800
				                       3600 3400 3200 3000 2800 2600 2400 2200
				                       2000 1800 1600 1400 1200 1000 900 800
				                       700 600 500 400 300 200 100 0>;
				qcom,lut-data = [00 00 26 a6 00 00 26 1d 00 00 27 32 00 00 27 7a 00 00 28 69 00 00 26 b9 00 00 26 cc 00 00 27 1e 00 00 27 b4 00 00 27 f2 00 00 26 d3 00 00 27 13 00 00 27 44 00 00 27 8c 00 00 27 e6 00 00 26 e9 00 00 27 09 00 00 27 55 00 00 27 5f 00 00 27 dd 00 00 26 e4 00 00 26 f7 00 00 27 4f 00 00 27 61 00 00 27 dd 00 00 26 cc 00 00 26 f0 00 00 27 42 00 00 27 74 00 00 27 e0 00 00 26 b5 00 00 26 ec 00 00 27 2c 00 00 27 84 00 00 27 e6 00 00 26 a6 00 00 26 ea 00 00 27 04 00 00 27 8f 00 00 27 f0 00 00 26 9a 00 00 26 ed 00 00 26 f3 00 00 27 99 00 00 27 ff 00 00 26 97 00 00 26 f3 00 00 26 fb 00 00 27 a2 00 00 28 10 00 00 26 9f 00 00 26 f7 00 00 27 06 00 00 27 ab 00 00 28 26 00 00 26 ab 00 00 26 fa 00 00 27 0c 00 00 27 b0 00 00 28 35 00 00 26 b4 00 00 26 ff 00 00 27 13 00 00 27 b0 00 00 28 3e 00 00 26 bb 00 00 27 7f 00 00 27 1a 00 00 27 af 00 00 28 43 00 00 26 c3 00 00 28 41 00 00 27 21 00 00 27 b4 00 00 28 3f 00 00 26 d1 00 00 28 4f 00 00 27 25 00 00 27 bb 00 00 28 38 00 00 26 dd 00 00 27 a8 00 00 27 24 00 00 27 ba 00 00 28 36 00 00 26 de 00 00 27 2c 00 00 27 1f 00 00 27 b3 00 00 28 36 00 00 26 d8 00 00 27 23 00 00 27 1d 00 00 27 ae 00 00 28 37 00 00 26 d4 00 00 27 1d 00 00 27 26 00 00 27 c2 00 00 28 43 00 00 26 d4 00 00 27 1f 00 00 27 37 00 00 27 e4 00 00 28 5b 00 00 26 d7 00 00 27 41 00 00 27 61 00 00 27 e9 00 00 28 5e 00 00 26 dc 00 00 27 5f 00 00 27 ab 00 00 27 dd 00 00 28 39 00 00 26 ea 00 00 27 5a 00 00 27 c4 00 00 27 c9 00 00 28 06 00 00 26 f5 00 00 27 4b 00 00 27 9d 00 00 27 8b 00 00 27 c4 00 00 26 f6 00 00 27 44 00 00 27 6e 00 00 27 42 00 00 27 81 00 00 26 f4 00 00 27 44 00 00 27 56 00 00 27 39 00 00 27 76 00 00 26 f4 00 00 27 45 00 00 27 45 00 00 27 3e 00 00 27 81 00 00 26 f5 00 00 27 3e 00 00 27 41 00 00 27 46 00 00 27 8f 00 00 26 f7 00 00 27 31 00 00 27 4c 00 00 27 50 00 00 27 9d 00 00 26 f8 00 00 27 2d 00 00 27 5b 00 00 27 5d 00 00 27 ae 00 00 26 fa 00 00 27 36 00 00 27 6b 00 00 27 72 00 00 27 c4 00 00 26 fc 00 00 27 44 00 00 27 7c 00 00 27 91 00 00 27 e0 00 00 26 ff 00 00 27 50 00 00 27 8f 00 00 27 b3 00 00 28 03 00 00 27 04 00 00 27 5d 00 00 27 a4 00 00 27 de 00 00 28 35 00 00 27 08 00 00 27 67 00 00 27 b8 00 00 28 04 00 00 28 69 00 00 27 0d 00 00 27 6f 00 00 27 c7 00 00 28 17 00 00 28 8c 00 00 27 13 00 00 27 76 00 00 27 d3 00 00 28 24 00 00 28 a9 00 00 27 1c 00 00 27 82 00 00 27 e0 00 00 28 2f 00 00 28 b1 00 00 27 27 00 00 27 92 00 00 27 f2 00 00 28 3a 00 00 28 a3 00 00 27 28 00 00 27 99 00 00 27 fd 00 00 28 42 00 00 28 96 00 00 27 1e 00 00 27 88 00 00 27 ec 00 00 28 44 00 00 28 95 00 00 27 18 00 00 27 7a 00 00 27 d0 00 00 28 43 00 00 28 90 00 00 27 16 00 00 27 7a 00 00 27 ca 00 00 28 3a 00 00 28 79 00 00 27 4a 00 00 27 8c 00 00 27 d7 00 00 28 3b 00 00 28 59 00 00 27 4d 00 00 27 8c 00 00 27 dc 00 00 28 45 00 00 28 78 00 00 27 46 00 00 27 81 00 00 27 e6 00 00 28 3d 00 00 28 77 00 00 27 44 00 00 27 6d 00 00 27 df 00 00 28 70 00 00 28 98 00 00 27 37 00 00 27 78 00 00 27 f3 00 00 28 9d 00 00 28 d4 00 00 26 f4 00 00 27 ab 00 00 27 f4 00 00 28 1c 00 00 28 0e 00 00 27 61 00 00 27 91 00 00 27 bb 00 00 27 d1 00 00 27 ea 00 00 27 32 00 00 27 6f 00 00 27 90 00 00 27 b1 00 00 27 bf 00 00 27 09 00 00 27 3b 00 00 27 77 00 00 27 90 00 00 27 a2 00 00 26 6c 00 00 27 09 00 00 27 49 00 00 27 63 00 00 27 4f 00 00 26 6c 00 00 27 09 00 00 27 49 00 00 27 63 00 00 27 4f 00 00 26 6c 00 00 27 09 00 00 27 49 00 00 27 63 00 00 27 4f];
			};

			qcom,pc-temp-z3-lut {
				qcom,lut-col-legend = <0 10 25 40 50>;
				qcom,lut-row-legend = <10000 9800 9600 9400 9200 9000 8800 8600
				                       8400 8200 8000 7800 7600 7400 7200 7000
				                       6800 6600 6400 6200 6000 5800 5600 5400
				                       5200 5000 4800 4600 4400 4200 4000 3800
				                       3600 3400 3200 3000 2800 2600 2400 2200
				                       2000 1800 1600 1400 1200 1000 900 800
				                       700 600 500 400 300 200 100 0>;
				qcom,lut-data = [00 00 4c 2c 00 00 4b f4 00 00 4b aa 00 00 4b 97 00 00 4b 71 00 00 4c aa 00 00 4c 40 00 00 4b ca 00 00 4b 99 00 00 4b 8c 00 00 4c dd 00 00 4c 68 00 00 4b e2 00 00 4b a2 00 00 4b 94 00 00 4c fa 00 00 4c 72 00 00 4b eb 00 00 4b a9 00 00 4b 99 00 00 4c fc 00 00 4c 77 00 00 4b e8 00 00 4b a9 00 00 4b 99 00 00 4c f8 00 00 4c 76 00 00 4b e3 00 00 4b a7 00 00 4b 97 00 00 4c f5 00 00 4c 6e 00 00 4b dd 00 00 4b a4 00 00 4b 94 00 00 4c f3 00 00 4c 65 00 00 4b d6 00 00 4b a0 00 00 4b 91 00 00 4c f1 00 00 4c 5d 00 00 4b d1 00 00 4b 9b 00 00 4b 8d 00 00 4c ec 00 00 4c 55 00 00 4b ce 00 00 4b 99 00 00 4b 8c 00 00 4c e0 00 00 4c 4f 00 00 4b cc 00 00 4b 98 00 00 4b 8b 00 00 4c d1 00 00 4c 49 00 00 4b c9 00 00 4b 97 00 00 4b 8a 00 00 4c c1 00 00 4c 45 00 00 4b c5 00 00 4b 97 00 00 4b 89 00 00 4c b0 00 00 4c 46 00 00 4b c3 00 00 4b 97 00 00 4b 88 00 00 4c a9 00 00 4c 49 00 00 4b c2 00 00 4b 96 00 00 4b 87 00 00 4c b0 00 00 4c 49 00 00 4b c2 00 00 4b 95 00 00 4b 83 00 00 4c b7 00 00 4c 43 00 00 4b c2 00 00 4b 94 00 00 4b 81 00 00 4c b6 00 00 4c 3d 00 00 4b c2 00 00 4b 93 00 00 4b 7f 00 00 4c ac 00 00 4c 36 00 00 4b c2 00 00 4b 91 00 00 4b 7d 00 00 4c a5 00 00 4c 2e 00 00 4b be 00 00 4b 8d 00 00 4b 7b 00 00 4c a2 00 00 4c 2d 00 00 4b b9 00 00 4b 87 00 00 4b 78 00 00 4c a0 00 00 4c 3b 00 00 4b bd 00 00 4b 89 00 00 4b 7a 00 00 4c a2 00 00 4c 47 00 00 4b ca 00 00 4b 9b 00 00 4b 8b 00 00 4c b0 00 00 4c 40 00 00 4b d7 00 00 4b a9 00 00 4b 9a 00 00 4c bb 00 00 4c 2f 00 00 4b e4 00 00 4b b0 00 00 4b 9d 00 00 4c b6 00 00 4c 2b 00 00 4b ed 00 00 4b b4 00 00 4b 9f 00 00 4c aa 00 00 4c 3f 00 00 4b ed 00 00 4b b4 00 00 4b 9f 00 00 4c a3 00 00 4c 53 00 00 4b ea 00 00 4b ad 00 00 4b 9c 00 00 4c a2 00 00 4c 53 00 00 4b e6 00 00 4b a8 00 00 4b 99 00 00 4c a2 00 00 4c 4f 00 00 4b e1 00 00 4b a6 00 00 4b 96 00 00 4c a3 00 00 4c 4a 00 00 4b da 00 00 4b a4 00 00 4b 93 00 00 4c a5 00 00 4c 44 00 00 4b d5 00 00 4b a2 00 00 4b 8f 00 00 4c a6 00 00 4c 3d 00 00 4b d1 00 00 4b 9e 00 00 4b 8c 00 00 4c a5 00 00 4c 38 00 00 4b cd 00 00 4b 9a 00 00 4b 88 00 00 4c a2 00 00 4c 34 00 00 4b c9 00 00 4b 95 00 00 4b 83 00 00 4c 9f 00 00 4c 31 00 00 4b c6 00 00 4b 92 00 00 4b 80 00 00 4c 9b 00 00 4c 2f 00 00 4b c5 00 00 4b 92 00 00 4b 82 00 00 4c 97 00 00 4c 2c 00 00 4b c4 00 00 4b 93 00 00 4b 88 00 00 4c 93 00 00 4c 29 00 00 4b c3 00 00 4b 94 00 00 4b 8b 00 00 4c 8d 00 00 4c 26 00 00 4b c1 00 00 4b 96 00 00 4b 8b 00 00 4c 89 00 00 4c 22 00 00 4b be 00 00 4b 97 00 00 4b 8b 00 00 4c 88 00 00 4c 1f 00 00 4b ba 00 00 4b 98 00 00 4b 8b 00 00 4c 84 00 00 4c 1b 00 00 4b b7 00 00 4b 99 00 00 4b 8b 00 00 4c 7b 00 00 4c 19 00 00 4b b9 00 00 4b 9a 00 00 4b 8d 00 00 4c 57 00 00 4c 0a 00 00 4b b6 00 00 4b 96 00 00 4b 8d 00 00 4c 49 00 00 4b fa 00 00 4b a8 00 00 4b 89 00 00 4b 79 00 00 4c 45 00 00 4b f8 00 00 4b a5 00 00 4b 83 00 00 4b 76 00 00 4c 43 00 00 4b ee 00 00 4b a3 00 00 4b 7c 00 00 4b 70 00 00 4c 21 00 00 4b ea 00 00 4b 9f 00 00 4b 78 00 00 4b 70 00 00 4b c9 00 00 4b ee 00 00 4b a3 00 00 4b 8e 00 00 4b 82 00 00 4c 3a 00 00 4b f2 00 00 4b b0 00 00 4b 91 00 00 4b 83 00 00 4c 34 00 00 4b f4 00 00 4b b2 00 00 4b 91 00 00 4b 84 00 00 4c 32 00 00 4b f7 00 00 4b b5 00 00 4b 92 00 00 4b 86 00 00 4c 17 00 00 4b fb 00 00 4b b3 00 00 4b 99 00 00 4b 8e 00 00 4c 17 00 00 4b fb 00 00 4b b3 00 00 4b 99 00 00 4b 8e 00 00 4c 17 00 00 4b fb 00 00 4b b3 00 00 4b 99 00 00 4b 8e];
			};

			qcom,pc-temp-z4-lut {
				qcom,lut-col-legend = <0 10 25 40 50>;
				qcom,lut-row-legend = <10000 9800 9600 9400 9200 9000 8800 8600
				                       8400 8200 8000 7800 7600 7400 7200 7000
				                       6800 6600 6400 6200 6000 5800 5600 5400
				                       5200 5000 4800 4600 4400 4200 4000 3800
				                       3600 3400 3200 3000 2800 2600 2400 2200
				                       2000 1800 1600 1400 1200 1000 900 800
				                       700 600 500 400 300 200 100 0>;
				qcom,lut-data = [00 00 3d e7 00 00 3c 2e 00 00 3a 96 00 00 39 c0 00 00 39 d8 00 00 3e 4d 00 00 3b fb 00 00 3a c4 00 00 3a 1e 00 00 39 e9 00 00 3d b2 00 00 3b b0 00 00 3a 6f 00 00 39 f6 00 00 39 ce 00 00 3c a4 00 00 3b 38 00 00 3a 20 00 00 39 be 00 00 39 99 00 00 3b e7 00 00 3a b0 00 00 39 e5 00 00 39 a3 00 00 39 85 00 00 3b 5f 00 00 3a 54 00 00 39 b8 00 00 39 8f 00 00 39 7d 00 00 3a f4 00 00 3a 0e 00 00 39 a8 00 00 39 84 00 00 39 78 00 00 3a 9f 00 00 39 e2 00 00 39 a0 00 00 39 7f 00 00 39 74 00 00 3a 5a 00 00 39 cb 00 00 39 99 00 00 39 7b 00 00 39 70 00 00 3a 2c 00 00 39 bd 00 00 39 90 00 00 39 76 00 00 39 6c 00 00 3a 0d 00 00 39 b6 00 00 39 88 00 00 39 70 00 00 39 68 00 00 39 f7 00 00 39 b3 00 00 39 82 00 00 39 6b 00 00 39 63 00 00 39 e7 00 00 39 b0 00 00 39 7c 00 00 39 65 00 00 39 5f 00 00 39 d9 00 00 39 9a 00 00 39 7a 00 00 39 60 00 00 39 5a 00 00 39 d5 00 00 39 7d 00 00 39 7a 00 00 39 5b 00 00 39 55 00 00 39 f5 00 00 39 7d 00 00 39 7a 00 00 39 57 00 00 39 50 00 00 3a 1d 00 00 39 ab 00 00 39 79 00 00 39 54 00 00 39 4d 00 00 3a 1d 00 00 39 ce 00 00 39 73 00 00 39 50 00 00 39 4a 00 00 39 fd 00 00 39 be 00 00 39 6c 00 00 39 4d 00 00 39 47 00 00 39 e3 00 00 39 9c 00 00 39 63 00 00 39 4b 00 00 39 44 00 00 39 d9 00 00 39 9c 00 00 39 5c 00 00 39 49 00 00 39 41 00 00 39 d2 00 00 3a 01 00 00 39 7d 00 00 39 54 00 00 39 46 00 00 39 e1 00 00 3a 5c 00 00 39 da 00 00 39 90 00 00 39 79 00 00 3a 4e 00 00 3a 5d 00 00 39 fc 00 00 39 b5 00 00 39 a0 00 00 3a aa 00 00 3a 54 00 00 39 da 00 00 39 a3 00 00 39 92 00 00 3a a3 00 00 3a 44 00 00 39 b1 00 00 39 85 00 00 39 77 00 00 3a 83 00 00 3a 16 00 00 39 9f 00 00 39 78 00 00 39 6b 00 00 3a 65 00 00 39 ea 00 00 39 93 00 00 39 72 00 00 39 65 00 00 3a 4a 00 00 39 db 00 00 39 8d 00 00 39 6d 00 00 39 60 00 00 3a 32 00 00 39 d3 00 00 39 8a 00 00 39 68 00 00 39 5c 00 00 3a 21 00 00 39 d0 00 00 39 88 00 00 39 65 00 00 39 59 00 00 3a 13 00 00 39 d0 00 00 39 88 00 00 39 63 00 00 39 56 00 00 3a 0b 00 00 39 d0 00 00 39 87 00 00 39 61 00 00 39 53 00 00 3a 07 00 00 39 d0 00 00 39 88 00 00 39 61 00 00 39 52 00 00 3a 05 00 00 39 d1 00 00 39 8a 00 00 39 61 00 00 39 51 00 00 3a 02 00 00 39 d1 00 00 39 8c 00 00 39 62 00 00 39 50 00 00 39 fd 00 00 39 d0 00 00 39 8d 00 00 39 66 00 00 39 54 00 00 39 fb 00 00 39 cf 00 00 39 8e 00 00 39 6d 00 00 39 5f 00 00 39 fe 00 00 39 d0 00 00 39 8f 00 00 39 6f 00 00 39 64 00 00 3a 03 00 00 39 d5 00 00 39 90 00 00 39 6d 00 00 39 63 00 00 3a 04 00 00 39 d7 00 00 39 91 00 00 39 6b 00 00 39 63 00 00 39 fb 00 00 39 cf 00 00 39 8d 00 00 39 68 00 00 39 63 00 00 39 ef 00 00 39 c2 00 00 39 84 00 00 39 64 00 00 39 62 00 00 39 e3 00 00 39 b8 00 00 39 7f 00 00 39 62 00 00 39 62 00 00 39 af 00 00 39 94 00 00 39 6f 00 00 39 56 00 00 39 54 00 00 39 94 00 00 39 76 00 00 39 58 00 00 39 3d 00 00 39 35 00 00 39 8b 00 00 39 6f 00 00 39 4c 00 00 39 37 00 00 39 2d 00 00 39 85 00 00 39 68 00 00 39 40 00 00 39 2d 00 00 39 23 00 00 39 95 00 00 39 64 00 00 39 3b 00 00 39 28 00 00 39 1e 00 00 39 f0 00 00 39 6b 00 00 39 46 00 00 39 31 00 00 39 31 00 00 39 93 00 00 39 73 00 00 39 45 00 00 39 35 00 00 39 36 00 00 39 9c 00 00 39 71 00 00 39 45 00 00 39 38 00 00 39 38 00 00 39 a0 00 00 39 70 00 00 39 45 00 00 39 3a 00 00 39 39 00 00 39 c5 00 00 39 6b 00 00 39 49 00 00 39 37 00 00 39 35 00 00 39 c5 00 00 39 6b 00 00 39 49 00 00 39 37 00 00 39 35 00 00 39 c5 00 00 39 6b 00 00 39 49 00 00 39 37 00 00 39 35];
			};

			qcom,pc-temp-z5-lut {
				qcom,lut-col-legend = <0 10 25 40 50>;
				qcom,lut-row-legend = <10000 9800 9600 9400 9200 9000 8800 8600
				                       8400 8200 8000 7800 7600 7400 7200 7000
				                       6800 6600 6400 6200 6000 5800 5600 5400
				                       5200 5000 4800 4600 4400 4200 4000 3800
				                       3600 3400 3200 3000 2800 2600 2400 2200
				                       2000 1800 1600 1400 1200 1000 900 800
				                       700 600 500 400 300 200 100 0>;
				qcom,lut-data = [00 00 2e 10 00 00 2f f7 00 00 34 df 00 00 3c 36 00 00 37 7c 00 00 32 c9 00 00 35 f0 00 00 3b 83 00 00 3f ff 00 00 44 08 00 00 36 11 00 00 3a fc 00 00 40 48 00 00 43 55 00 00 4a 85 00 00 38 b2 00 00 3e e8 00 00 44 7d 00 00 47 8b 00 00 50 25 00 00 3b 09 00 00 42 84 00 00 49 42 00 00 4b 2c 00 00 52 fd 00 00 3d 49 00 00 47 05 00 00 4c c2 00 00 4e b2 00 00 54 ef 00 00 3f f7 00 00 4c 89 00 00 4c e3 00 00 4f bc 00 00 55 9b 00 00 43 c9 00 00 51 10 00 00 4c 13 00 00 4e 60 00 00 54 28 00 00 48 8a 00 00 54 67 00 00 4b b9 00 00 4d 0e 00 00 52 4d 00 00 4d 02 00 00 57 28 00 00 4d 7d 00 00 4d 79 00 00 52 7f 00 00 51 ba 00 00 58 60 00 00 4f 90 00 00 4f 03 00 00 54 58 00 00 54 96 00 00 58 79 00 00 4f 8e 00 00 50 e0 00 00 56 77 00 00 53 f6 00 00 59 08 00 00 4e de 00 00 53 a1 00 00 59 23 00 00 52 51 00 00 5f 48 00 00 4e 9f 00 00 56 71 00 00 5b b6 00 00 52 19 00 00 68 8c 00 00 50 68 00 00 58 e5 00 00 5c d7 00 00 58 1b 00 00 69 3d 00 00 52 66 00 00 5b 5a 00 00 5c ad 00 00 5f 1d 00 00 5f 87 00 00 52 de 00 00 5c f9 00 00 5c 67 00 00 5e 98 00 00 58 14 00 00 53 bf 00 00 5e f9 00 00 5d 46 00 00 59 74 00 00 59 45 00 00 55 44 00 00 60 17 00 00 5e 93 00 00 56 96 00 00 5d 7a 00 00 5a d2 00 00 5f 9a 00 00 5f e9 00 00 5a 1b 00 00 64 d5 00 00 60 03 00 00 5e 41 00 00 61 80 00 00 62 82 00 00 79 a8 00 00 5e 61 00 00 5b 4b 00 00 61 07 00 00 6c 55 00 00 8a 09 00 00 58 9a 00 00 54 90 00 00 5a 47 00 00 7b 8c 00 00 7a f6 00 00 54 d4 00 00 50 c2 00 00 54 c9 00 00 85 29 00 00 56 e2 00 00 52 be 00 00 51 cd 00 00 53 f5 00 00 7c 79 00 00 4a aa 00 00 51 8f 00 00 53 93 00 00 53 a0 00 00 67 a8 00 00 51 94 00 00 54 2d 00 00 54 8b 00 00 54 72 00 00 5d b1 00 00 5a f0 00 00 5b cf 00 00 55 73 00 00 58 76 00 00 5b cf 00 00 61 e7 00 00 61 86 00 00 56 ef 00 00 5c ea 00 00 5b 44 00 00 68 68 00 00 65 07 00 00 5c 11 00 00 60 59 00 00 5d 42 00 00 6c 77 00 00 68 03 00 00 62 e4 00 00 63 c1 00 00 62 fb 00 00 6e f4 00 00 6a e6 00 00 67 b5 00 00 67 c5 00 00 67 d4 00 00 70 8c 00 00 6d 93 00 00 6b ff 00 00 6c 87 00 00 6a a3 00 00 71 18 00 00 6f dd 00 00 6e d1 00 00 6f 16 00 00 6c d3 00 00 71 55 00 00 72 3c 00 00 70 fa 00 00 6f bd 00 00 6d df 00 00 71 34 00 00 73 9c 00 00 72 55 00 00 70 4d 00 00 6d d9 00 00 6f d8 00 00 72 aa 00 00 71 00 00 00 71 50 00 00 6d 83 00 00 6d a7 00 00 6f c5 00 00 6d 42 00 00 72 d5 00 00 6d 80 00 00 6b 58 00 00 6c 18 00 00 6b ed 00 00 74 8e 00 00 6d 78 00 00 68 6b 00 00 66 22 00 00 6c 1d 00 00 78 31 00 00 6c f1 00 00 65 50 00 00 60 32 00 00 6c 83 00 00 7b 79 00 00 6b 2c 00 00 61 66 00 00 5b 49 00 00 6f 12 00 00 7c 39 00 00 69 31 00 00 5f 44 00 00 57 e3 00 00 72 b8 00 00 7c 8f 00 00 67 35 00 00 5f 82 00 00 58 50 00 00 71 08 00 00 7c c1 00 00 6d 54 00 00 64 3f 00 00 59 44 00 00 66 fd 00 00 79 d1 00 00 6b 26 00 00 63 6d 00 00 55 d4 00 00 58 62 00 00 52 6b 00 00 67 ba 00 00 64 02 00 00 57 50 00 00 58 48 00 00 56 c3 00 00 68 b6 00 00 5d 6a 00 00 5f 29 00 00 58 f7 00 00 5f 82 00 00 5b b6 00 00 5c 59 00 00 60 a0 00 00 5a bb 00 00 71 08 00 00 4a 02 00 00 5d 61 00 00 56 d4 00 00 71 2b 00 00 74 14 00 00 5c 09 00 00 54 cb 00 00 5d b6 00 00 6b 3b 00 00 66 df 00 00 4f 6d 00 00 53 e2 00 00 5c 31 00 00 62 3e 00 00 60 2b 00 00 4a 17 00 00 52 04 00 00 5c 36 00 00 5b 47 00 00 59 d5 00 00 41 9c 00 00 52 70 00 00 54 95 00 00 5f af 00 00 5c a4 00 00 41 9c 00 00 52 70 00 00 54 95 00 00 5f af 00 00 5c a4 00 00 41 9c 00 00 52 70 00 00 54 95 00 00 5f af 00 00 5c a4];
			};

			qcom,pc-temp-z6-lut {
				qcom,lut-col-legend = <0 10 25 40 50>;
				qcom,lut-row-legend = <10000 9800 9600 9400 9200 9000 8800 8600
				                       8400 8200 8000 7800 7600 7400 7200 7000
				                       6800 6600 6400 6200 6000 5800 5600 5400
				                       5200 5000 4800 4600 4400 4200 4000 3800
				                       3600 3400 3200 3000 2800 2600 2400 2200
				                       2000 1800 1600 1400 1200 1000 900 800
				                       700 600 500 400 300 200 100 0>;
				qcom,lut-data = [00 00 3d a0 00 00 3a e9 00 00 38 ee 00 00 38 43 00 00 38 2a 00 00 3d ce 00 00 3a da 00 00 39 13 00 00 38 79 00 00 38 4c 00 00 3d 70 00 00 3a c2 00 00 38 fb 00 00 38 6c 00 00 38 44 00 00 3c c9 00 00 3a 89 00 00 38 e0 00 00 38 59 00 00 38 32 00 00 3c 4a 00 00 3a 35 00 00 38 c3 00 00 38 4c 00 00 38 28 00 00 3b e4 00 00 39 f8 00 00 38 a8 00 00 38 42 00 00 38 23 00 00 3b 92 00 00 39 c6 00 00 38 9b 00 00 38 3a 00 00 38 1f 00 00 3b 50 00 00 39 a3 00 00 38 92 00 00 38 35 00 00 38 1a 00 00 3b 1a 00 00 39 90 00 00 38 8b 00 00 38 30 00 00 38 17 00 00 3a f0 00 00 39 83 00 00 38 85 00 00 38 2c 00 00 38 14 00 00 3a d1 00 00 39 7b 00 00 38 80 00 00 38 29 00 00 38 11 00 00 3a b9 00 00 39 76 00 00 38 7b 00 00 38 26 00 00 38 0e 00 00 3a a6 00 00 39 70 00 00 38 76 00 00 38 23 00 00 38 0c 00 00 3a 95 00 00 39 65 00 00 38 73 00 00 38 20 00 00 38 09 00 00 3a 8f 00 00 39 58 00 00 38 72 00 00 38 1e 00 00 38 06 00 00 3a 9a 00 00 39 57 00 00 38 71 00 00 38 1b 00 00 38 02 00 00 3a a9 00 00 39 63 00 00 38 70 00 00 38 19 00 00 37 ff 00 00 3a a8 00 00 39 6d 00 00 38 6e 00 00 38 17 00 00 37 fd 00 00 3a 97 00 00 39 65 00 00 38 6b 00 00 38 15 00 00 37 fb 00 00 3a 8b 00 00 39 54 00 00 38 66 00 00 38 12 00 00 37 f8 00 00 3a 89 00 00 39 54 00 00 38 61 00 00 38 0e 00 00 37 f6 00 00 3a 89 00 00 39 89 00 00 38 73 00 00 38 15 00 00 37 f9 00 00 3a 94 00 00 39 b9 00 00 38 a4 00 00 38 3a 00 00 38 1a 00 00 3a ce 00 00 39 b7 00 00 38 b7 00 00 38 51 00 00 38 33 00 00 3a fd 00 00 39 af 00 00 38 b0 00 00 38 4c 00 00 38 2f 00 00 3a f9 00 00 39 a7 00 00 38 a7 00 00 38 44 00 00 38 26 00 00 3a e8 00 00 39 a0 00 00 38 a1 00 00 38 3e 00 00 38 20 00 00 3a db 00 00 39 9a 00 00 38 9c 00 00 38 39 00 00 38 1d 00 00 3a d1 00 00 39 96 00 00 38 98 00 00 38 35 00 00 38 1a 00 00 3a ca 00 00 39 93 00 00 38 94 00 00 38 32 00 00 38 16 00 00 3a c7 00 00 39 91 00 00 38 92 00 00 38 30 00 00 38 14 00 00 3a c5 00 00 39 8f 00 00 38 90 00 00 38 2e 00 00 38 11 00 00 3a c5 00 00 39 8e 00 00 38 8e 00 00 38 2b 00 00 38 0e 00 00 3a c6 00 00 39 8e 00 00 38 8e 00 00 38 2a 00 00 38 0b 00 00 3a c7 00 00 39 8f 00 00 38 8e 00 00 38 28 00 00 38 09 00 00 3a c9 00 00 39 90 00 00 38 8f 00 00 38 27 00 00 38 07 00 00 3a ca 00 00 39 92 00 00 38 90 00 00 38 29 00 00 38 09 00 00 3a cc 00 00 39 94 00 00 38 91 00 00 38 2d 00 00 38 12 00 00 3a cf 00 00 39 97 00 00 38 92 00 00 38 30 00 00 38 16 00 00 3a d5 00 00 39 9b 00 00 38 94 00 00 38 30 00 00 38 16 00 00 3a d9 00 00 39 9d 00 00 38 95 00 00 38 31 00 00 38 17 00 00 3a da 00 00 39 9b 00 00 38 92 00 00 38 31 00 00 38 17 00 00 3a db 00 00 39 9a 00 00 38 8e 00 00 38 31 00 00 38 18 00 00 3a db 00 00 39 99 00 00 38 8e 00 00 38 31 00 00 38 19 00 00 3a c7 00 00 39 8c 00 00 38 89 00 00 38 2a 00 00 38 14 00 00 3a bb 00 00 39 7c 00 00 38 79 00 00 38 1a 00 00 37 fd 00 00 3a b6 00 00 39 78 00 00 38 73 00 00 38 14 00 00 37 f7 00 00 3a b3 00 00 39 72 00 00 38 6d 00 00 38 0c 00 00 37 f0 00 00 3a ac 00 00 39 70 00 00 38 6a 00 00 38 08 00 00 37 ee 00 00 3a af 00 00 39 7a 00 00 38 72 00 00 38 18 00 00 38 00 00 00 3a c6 00 00 39 84 00 00 38 7b 00 00 38 1e 00 00 38 05 00 00 3a cf 00 00 39 8a 00 00 38 7e 00 00 38 20 00 00 38 08 00 00 3a dc 00 00 39 93 00 00 38 83 00 00 38 23 00 00 38 0b 00 00 3a f0 00 00 39 9f 00 00 38 88 00 00 38 28 00 00 38 0f 00 00 3a f0 00 00 39 9f 00 00 38 88 00 00 38 28 00 00 38 0f 00 00 3a f0 00 00 39 9f 00 00 38 88 00 00 38 28 00 00 38 0f];
			};

			qcom,pc-temp-y1-lut {
				qcom,lut-col-legend = <0xfffffff6 0 10 25 40 50>;
				qcom,lut-row-legend = <10000 9800 9600 9400 9200 9000 8800 8600
				                       8400 8200 8000 7800 7600 7400 7200 7000
				                       6800 6600 6400 6200 6000 5800 5600 5400
				                       5200 5000 4800 4600 4400 4200 4000 3800
				                       3600 3400 3200 3000 2800 2600 2400 2200
				                       2000 1800 1600 1400 1200 1000 900 800
				                       700 600 500 400 300 200 100 0>;
				qcom,lut-data = [00 00 16 bd 00 00 14 e3 00 00 13 ad 00 00 12 42 00 00 11 81 00 00 11 4b 00 00 16 d3 00 00 14 e7 00 00 13 ac 00 00 12 40 00 00 11 84 00 00 11 4d 00 00 16 e9 00 00 14 eb 00 00 13 ab 00 00 12 3e 00 00 11 85 00 00 11 4e 00 00 16 fb 00 00 14 f1 00 00 13 a9 00 00 12 3b 00 00 11 85 00 00 11 4e 00 00 17 09 00 00 14 f5 00 00 13 a7 00 00 12 38 00 00 11 84 00 00 11 4f 00 00 17 0f 00 00 14 f7 00 00 13 a6 00 00 12 34 00 00 11 82 00 00 11 4f 00 00 17 0c 00 00 14 f7 00 00 13 a1 00 00 12 30 00 00 11 7d 00 00 11 4e 00 00 17 07 00 00 14 f5 00 00 13 9b 00 00 12 2a 00 00 11 79 00 00 11 4d 00 00 17 08 00 00 14 f4 00 00 13 96 00 00 12 26 00 00 11 78 00 00 11 4b 00 00 17 0d 00 00 14 ef 00 00 13 92 00 00 12 23 00 00 11 78 00 00 11 49 00 00 17 0f 00 00 14 ec 00 00 13 90 00 00 12 20 00 00 11 78 00 00 11 47 00 00 17 10 00 00 14 ee 00 00 13 93 00 00 12 1d 00 00 11 76 00 00 11 46 00 00 17 14 00 00 14 f1 00 00 13 97 00 00 12 1a 00 00 11 74 00 00 11 46 00 00 17 17 00 00 14 f1 00 00 13 95 00 00 12 18 00 00 11 73 00 00 11 45 00 00 17 20 00 00 14 ef 00 00 13 8c 00 00 12 16 00 00 11 71 00 00 11 43 00 00 17 25 00 00 14 ee 00 00 13 88 00 00 12 15 00 00 11 70 00 00 11 43 00 00 17 22 00 00 14 f5 00 00 13 8b 00 00 12 15 00 00 11 70 00 00 11 43 00 00 17 1d 00 00 14 fe 00 00 13 8f 00 00 12 15 00 00 11 70 00 00 11 43 00 00 17 1d 00 00 15 00 00 00 13 90 00 00 12 15 00 00 11 70 00 00 11 43 00 00 17 1c 00 00 14 fd 00 00 13 8d 00 00 12 16 00 00 11 71 00 00 11 43 00 00 17 1a 00 00 14 fc 00 00 13 8b 00 00 12 17 00 00 11 71 00 00 11 43 00 00 17 1a 00 00 15 01 00 00 13 8c 00 00 12 19 00 00 11 73 00 00 11 44 00 00 17 1c 00 00 15 06 00 00 13 8d 00 00 12 1b 00 00 11 75 00 00 11 46 00 00 17 1d 00 00 15 07 00 00 13 8d 00 00 12 1e 00 00 11 75 00 00 11 46 00 00 17 1d 00 00 15 06 00 00 13 8e 00 00 12 20 00 00 11 75 00 00 11 46 00 00 17 1d 00 00 15 06 00 00 13 90 00 00 12 23 00 00 11 76 00 00 11 47 00 00 17 1b 00 00 15 0e 00 00 13 95 00 00 12 26 00 00 11 78 00 00 11 47 00 00 17 17 00 00 15 18 00 00 13 9b 00 00 12 2a 00 00 11 7a 00 00 11 48 00 00 17 13 00 00 15 19 00 00 13 a0 00 00 12 2e 00 00 11 7c 00 00 11 4a 00 00 17 0c 00 00 15 16 00 00 13 a5 00 00 12 33 00 00 11 7f 00 00 11 4c 00 00 17 08 00 00 15 13 00 00 13 a8 00 00 12 38 00 00 11 81 00 00 11 4e 00 00 17 12 00 00 15 13 00 00 13 a8 00 00 12 3d 00 00 11 84 00 00 11 4f 00 00 17 22 00 00 15 16 00 00 13 a8 00 00 12 43 00 00 11 87 00 00 11 50 00 00 17 2c 00 00 15 19 00 00 13 ab 00 00 12 47 00 00 11 8a 00 00 11 52 00 00 17 37 00 00 15 1b 00 00 13 b3 00 00 12 4a 00 00 11 8d 00 00 11 55 00 00 17 3a 00 00 15 1d 00 00 13 b7 00 00 12 4e 00 00 11 90 00 00 11 58 00 00 17 2d 00 00 15 19 00 00 13 b7 00 00 12 53 00 00 11 93 00 00 11 5a 00 00 17 18 00 00 15 13 00 00 13 b8 00 00 12 57 00 00 11 95 00 00 11 5c 00 00 17 0d 00 00 15 11 00 00 13 bd 00 00 12 5d 00 00 11 98 00 00 11 5d 00 00 17 04 00 00 15 11 00 00 13 c5 00 00 12 63 00 00 11 9a 00 00 11 5e 00 00 16 ff 00 00 15 11 00 00 13 c9 00 00 12 66 00 00 11 9d 00 00 11 60 00 00 17 08 00 00 15 12 00 00 13 c8 00 00 12 69 00 00 11 9f 00 00 11 63 00 00 17 0c 00 00 15 16 00 00 13 ca 00 00 12 6b 00 00 11 a1 00 00 11 63 00 00 16 fb 00 00 15 2a 00 00 13 d7 00 00 12 6d 00 00 11 a3 00 00 11 63 00 00 17 1b 00 00 15 22 00 00 13 d3 00 00 12 75 00 00 11 a6 00 00 11 66 00 00 17 12 00 00 15 17 00 00 13 e1 00 00 12 76 00 00 11 a9 00 00 11 68 00 00 17 0b 00 00 15 1a 00 00 13 e0 00 00 12 77 00 00 11 a7 00 00 11 69 00 00 17 05 00 00 15 18 00 00 13 d9 00 00 12 7e 00 00 11 aa 00 00 11 69 00 00 17 06 00 00 15 28 00 00 13 da 00 00 12 81 00 00 11 a9 00 00 11 69 00 00 17 05 00 00 15 2e 00 00 13 e1 00 00 12 7f 00 00 11 ab 00 00 11 6a 00 00 17 3f 00 00 15 1b 00 00 13 eb 00 00 12 82 00 00 11 ad 00 00 11 6c 00 00 17 5a 00 00 15 23 00 00 13 ec 00 00 12 90 00 00 11 b1 00 00 11 6e 00 00 17 37 00 00 15 1e 00 00 13 f3 00 00 12 8c 00 00 11 b6 00 00 11 70 00 00 17 43 00 00 15 2c 00 00 13 f4 00 00 12 95 00 00 11 b8 00 00 11 75 00 00 17 43 00 00 15 2c 00 00 13 f4 00 00 12 95 00 00 11 b8 00 00 11 75 00 00 17 43 00 00 15 2c 00 00 13 f4 00 00 12 95 00 00 11 b8 00 00 11 75];
			};

			qcom,pc-temp-y2-lut {
				qcom,lut-col-legend = <0xfffffff6 0 10 25 40 50>;
				qcom,lut-row-legend = <10000 9800 9600 9400 9200 9000 8800 8600
				                       8400 8200 8000 7800 7600 7400 7200 7000
				                       6800 6600 6400 6200 6000 5800 5600 5400
				                       5200 5000 4800 4600 4400 4200 4000 3800
				                       3600 3400 3200 3000 2800 2600 2400 2200
				                       2000 1800 1600 1400 1200 1000 900 800
				                       700 600 500 400 300 200 100 0>;
				qcom,lut-data = [00 00 27 6b 00 00 28 07 00 00 29 0d 00 00 2a 0f 00 00 2a 21 00 00 2a af 00 00 27 65 00 00 28 13 00 00 29 04 00 00 29 f4 00 00 2a 37 00 00 2a ce 00 00 27 62 00 00 28 22 00 00 28 f9 00 00 29 d7 00 00 2a 42 00 00 2a de 00 00 27 62 00 00 28 30 00 00 28 ef 00 00 29 bc 00 00 2a 45 00 00 2a e2 00 00 27 64 00 00 28 3d 00 00 28 e6 00 00 29 a5 00 00 2a 42 00 00 2a de 00 00 27 68 00 00 28 45 00 00 28 df 00 00 29 93 00 00 2a 3d 00 00 2a d7 00 00 27 91 00 00 28 4a 00 00 28 da 00 00 29 86 00 00 2a 23 00 00 2a c4 00 00 27 d4 00 00 28 4e 00 00 28 d6 00 00 29 7b 00 00 2a 02 00 00 2a a8 00 00 28 02 00 00 28 4d 00 00 28 d4 00 00 29 6e 00 00 29 fc 00 00 2a 8b 00 00 28 45 00 00 28 46 00 00 28 d0 00 00 29 5d 00 00 29 fd 00 00 2a 66 00 00 28 67 00 00 28 42 00 00 28 ce 00 00 29 52 00 00 29 fe 00 00 2a 51 00 00 28 6c 00 00 28 6d 00 00 28 d3 00 00 29 55 00 00 29 f8 00 00 2a 52 00 00 28 79 00 00 28 c1 00 00 28 de 00 00 29 5c 00 00 29 ef 00 00 2a 55 00 00 28 72 00 00 29 14 00 00 28 f2 00 00 29 5c 00 00 29 ee 00 00 2a 51 00 00 28 1b 00 00 29 79 00 00 29 1d 00 00 29 59 00 00 29 ed 00 00 2a 46 00 00 27 d4 00 00 29 af 00 00 29 51 00 00 29 5f 00 00 29 ed 00 00 2a 40 00 00 27 09 00 00 29 b5 00 00 29 96 00 00 29 7e 00 00 29 ed 00 00 2a 48 00 00 25 fc 00 00 29 b7 00 00 29 d5 00 00 29 ae 00 00 29 ee 00 00 2a 55 00 00 25 cd 00 00 29 ba 00 00 29 ec 00 00 29 f5 00 00 29 ec 00 00 2a 5f 00 00 25 c7 00 00 29 c1 00 00 29 f9 00 00 2a 59 00 00 29 e9 00 00 2a 69 00 00 25 c4 00 00 29 c4 00 00 29 fe 00 00 2a 7d 00 00 29 f0 00 00 2a 79 00 00 25 c2 00 00 29 c7 00 00 29 fb 00 00 2a 4c 00 00 2a 51 00 00 2a a2 00 00 25 c0 00 00 29 cd 00 00 29 f7 00 00 2a 17 00 00 2a bc 00 00 2a d5 00 00 25 bf 00 00 29 ca 00 00 2a 02 00 00 2a 20 00 00 2a cc 00 00 2a f7 00 00 25 bd 00 00 29 b4 00 00 2a 19 00 00 2a 48 00 00 2a d0 00 00 2b 16 00 00 25 bc 00 00 29 90 00 00 2a 28 00 00 2a 69 00 00 2a d5 00 00 2b 2e 00 00 25 bb 00 00 29 37 00 00 2a 2e 00 00 2a 80 00 00 2a dc 00 00 2b 46 00 00 25 ba 00 00 28 b0 00 00 2a 35 00 00 2a 94 00 00 2a e4 00 00 2b 5e 00 00 25 b9 00 00 28 2f 00 00 2a 44 00 00 2a a4 00 00 2a f2 00 00 2b 71 00 00 25 b8 00 00 27 96 00 00 2a 5f 00 00 2a b2 00 00 2b 0d 00 00 2b 81 00 00 25 b8 00 00 27 1a 00 00 2a 6a 00 00 2a c4 00 00 2b 28 00 00 2b 94 00 00 25 b7 00 00 26 b9 00 00 2a 5c 00 00 2a ed 00 00 2b 45 00 00 2b b1 00 00 25 b7 00 00 26 69 00 00 2a 48 00 00 2b 0e 00 00 2b 61 00 00 2b ca 00 00 25 b6 00 00 26 3f 00 00 2a 37 00 00 2b 0d 00 00 2b 81 00 00 2b d4 00 00 25 b6 00 00 26 21 00 00 2a 22 00 00 2b 03 00 00 2b a2 00 00 2b da 00 00 25 b6 00 00 26 09 00 00 2a 10 00 00 2a fd 00 00 2b a9 00 00 2b dc 00 00 25 b6 00 00 25 f4 00 00 2a 01 00 00 2b 03 00 00 2b 83 00 00 2b c0 00 00 25 b6 00 00 25 e3 00 00 29 f1 00 00 2b 09 00 00 2b 5e 00 00 2b a2 00 00 25 b5 00 00 25 d9 00 00 29 d8 00 00 2b 04 00 00 2b 58 00 00 2b 99 00 00 25 b5 00 00 25 d1 00 00 29 b3 00 00 2a f4 00 00 2b 55 00 00 2b 88 00 00 25 b5 00 00 25 cb 00 00 29 78 00 00 2a e4 00 00 2b 49 00 00 2b 6e 00 00 25 b5 00 00 25 c7 00 00 28 fb 00 00 2a d1 00 00 2b 18 00 00 2b 3a 00 00 25 b5 00 00 25 c3 00 00 28 89 00 00 2a b8 00 00 2b 01 00 00 2b 30 00 00 25 b5 00 00 25 c0 00 00 28 2c 00 00 2a 96 00 00 2a fa 00 00 2b 58 00 00 25 b5 00 00 25 bd 00 00 27 dd 00 00 2a 73 00 00 2a f8 00 00 2a f5 00 00 25 b4 00 00 25 bb 00 00 27 cd 00 00 2a 44 00 00 2a b7 00 00 2a bd 00 00 25 b4 00 00 25 bb 00 00 27 ba 00 00 2a 5a 00 00 2a 80 00 00 2a 9b 00 00 25 b4 00 00 25 ba 00 00 28 1a 00 00 2a 22 00 00 2a 9b 00 00 2a 92 00 00 25 b4 00 00 25 b9 00 00 28 66 00 00 2a 43 00 00 2a ae 00 00 2a 9c 00 00 25 b4 00 00 25 b8 00 00 28 0a 00 00 2a 47 00 00 2a 7b 00 00 2a 63 00 00 25 b4 00 00 25 b7 00 00 27 35 00 00 29 fe 00 00 2a 4d 00 00 2a 32 00 00 25 b4 00 00 25 b6 00 00 26 f4 00 00 29 9b 00 00 29 fe 00 00 2a 0e 00 00 25 b3 00 00 25 b5 00 00 26 a3 00 00 29 ef 00 00 29 c2 00 00 29 b3 00 00 25 b2 00 00 25 b5 00 00 27 bb 00 00 29 b7 00 00 29 49 00 00 29 30 00 00 25 b2 00 00 25 b5 00 00 27 bb 00 00 29 b7 00 00 29 49 00 00 29 30 00 00 25 b2 00 00 25 b5 00 00 27 bb 00 00 29 b7 00 00 29 49 00 00 29 30];
			};

			qcom,pc-temp-y3-lut {
				qcom,lut-col-legend = <0xfffffff6 0 10 25 40 50>;
				qcom,lut-row-legend = <10000 9800 9600 9400 9200 9000 8800 8600
				                       8400 8200 8000 7800 7600 7400 7200 7000
				                       6800 6600 6400 6200 6000 5800 5600 5400
				                       5200 5000 4800 4600 4400 4200 4000 3800
				                       3600 3400 3200 3000 2800 2600 2400 2200
				                       2000 1800 1600 1400 1200 1000 900 800
				                       700 600 500 400 300 200 100 0>;
				qcom,lut-data = [00 00 36 c4 00 00 34 ad 00 00 34 24 00 00 33 ea 00 00 33 dc 00 00 33 d5 00 00 36 58 00 00 34 ac 00 00 34 26 00 00 33 ea 00 00 33 dc 00 00 33 d6 00 00 36 17 00 00 34 aa 00 00 34 27 00 00 33 ea 00 00 33 dd 00 00 33 d7 00 00 35 f6 00 00 34 a9 00 00 34 28 00 00 33 ea 00 00 33 dd 00 00 33 d8 00 00 35 ea 00 00 34 a7 00 00 34 29 00 00 33 ea 00 00 33 de 00 00 33 da 00 00 35 e8 00 00 34 a5 00 00 34 29 00 00 33 ea 00 00 33 de 00 00 33 da 00 00 36 16 00 00 34 a2 00 00 34 29 00 00 33 ea 00 00 33 de 00 00 33 db 00 00 36 5b 00 00 34 9f 00 00 34 29 00 00 33 e9 00 00 33 df 00 00 33 db 00 00 36 39 00 00 34 a0 00 00 34 29 00 00 33 ea 00 00 33 df 00 00 33 db 00 00 35 4e 00 00 34 a5 00 00 34 28 00 00 33 eb 00 00 33 df 00 00 33 db 00 00 34 bb 00 00 34 a8 00 00 34 27 00 00 33 ec 00 00 33 e0 00 00 33 db 00 00 34 df 00 00 34 9e 00 00 34 27 00 00 33 ee 00 00 33 e0 00 00 33 dc 00 00 35 18 00 00 34 8e 00 00 34 27 00 00 33 f0 00 00 33 e0 00 00 33 dd 00 00 35 25 00 00 34 89 00 00 34 28 00 00 33 f1 00 00 33 e1 00 00 33 dd 00 00 35 15 00 00 34 82 00 00 34 2c 00 00 33 f1 00 00 33 e2 00 00 33 dd 00 00 35 06 00 00 34 7c 00 00 34 2e 00 00 33 f2 00 00 33 e2 00 00 33 dd 00 00 34 e8 00 00 34 7a 00 00 34 28 00 00 33 f2 00 00 33 e2 00 00 33 dd 00 00 34 c3 00 00 34 75 00 00 34 1f 00 00 33 f4 00 00 33 e3 00 00 33 dd 00 00 34 bf 00 00 34 6d 00 00 34 1d 00 00 33 f5 00 00 33 e4 00 00 33 de 00 00 34 c6 00 00 34 5b 00 00 34 1c 00 00 33 f6 00 00 33 e5 00 00 33 e0 00 00 34 cd 00 00 34 49 00 00 34 1a 00 00 33 f7 00 00 33 e6 00 00 33 e1 00 00 34 d1 00 00 34 3c 00 00 34 13 00 00 33 f2 00 00 33 e2 00 00 33 de 00 00 34 d3 00 00 34 31 00 00 34 0b 00 00 33 eb 00 00 33 de 00 00 33 db 00 00 34 d3 00 00 34 28 00 00 34 07 00 00 33 e8 00 00 33 dd 00 00 33 da 00 00 34 dd 00 00 34 21 00 00 34 04 00 00 33 e6 00 00 33 dd 00 00 33 d9 00 00 34 f1 00 00 34 1a 00 00 34 02 00 00 33 e5 00 00 33 dc 00 00 33 d8 00 00 35 19 00 00 34 08 00 00 33 ff 00 00 33 e5 00 00 33 dd 00 00 33 d9 00 00 35 4e 00 00 33 f3 00 00 33 fd 00 00 33 e5 00 00 33 dd 00 00 33 d9 00 00 35 80 00 00 33 e8 00 00 33 fc 00 00 33 e5 00 00 33 dc 00 00 33 d9 00 00 35 b6 00 00 33 d7 00 00 33 fb 00 00 33 e6 00 00 33 dc 00 00 33 d9 00 00 35 ee 00 00 33 d2 00 00 33 f9 00 00 33 e6 00 00 33 db 00 00 33 d9 00 00 36 2a 00 00 33 d4 00 00 33 f7 00 00 33 e5 00 00 33 db 00 00 33 d9 00 00 36 69 00 00 33 d7 00 00 33 f5 00 00 33 e5 00 00 33 db 00 00 33 d8 00 00 36 aa 00 00 33 da 00 00 33 f5 00 00 33 e5 00 00 33 db 00 00 33 d8 00 00 36 ec 00 00 33 de 00 00 33 f7 00 00 33 e4 00 00 33 dc 00 00 33 d8 00 00 37 36 00 00 33 e4 00 00 33 f9 00 00 33 e4 00 00 33 dd 00 00 33 d8 00 00 37 8c 00 00 33 ef 00 00 33 fb 00 00 33 e3 00 00 33 dc 00 00 33 d9 00 00 37 e8 00 00 33 ff 00 00 33 fd 00 00 33 e2 00 00 33 db 00 00 33 d9 00 00 38 45 00 00 34 14 00 00 33 ff 00 00 33 e2 00 00 33 db 00 00 33 d9 00 00 38 a5 00 00 34 32 00 00 34 00 00 00 33 e2 00 00 33 dc 00 00 33 da 00 00 39 04 00 00 34 51 00 00 34 01 00 00 33 e2 00 00 33 dc 00 00 33 da 00 00 39 5f 00 00 34 68 00 00 34 01 00 00 33 e2 00 00 33 dd 00 00 33 da 00 00 39 bd 00 00 34 83 00 00 34 02 00 00 33 e3 00 00 33 dd 00 00 33 da 00 00 3a 24 00 00 34 b0 00 00 34 05 00 00 33 e4 00 00 33 dc 00 00 33 d9 00 00 3a 96 00 00 34 fd 00 00 34 0a 00 00 33 e5 00 00 33 dc 00 00 33 da 00 00 3a 8c 00 00 35 1c 00 00 34 0e 00 00 33 e8 00 00 33 de 00 00 33 dc 00 00 3a d3 00 00 35 51 00 00 34 12 00 00 33 e9 00 00 33 df 00 00 33 dd 00 00 3b 30 00 00 35 90 00 00 34 1b 00 00 33 ee 00 00 33 e3 00 00 33 df 00 00 3b 8f 00 00 35 d8 00 00 34 27 00 00 33 f0 00 00 33 e2 00 00 33 dd 00 00 3b ec 00 00 36 17 00 00 34 28 00 00 33 ef 00 00 33 e0 00 00 33 dc 00 00 3c 53 00 00 36 62 00 00 34 2b 00 00 33 ef 00 00 33 e1 00 00 33 dd 00 00 3d 0b 00 00 36 ec 00 00 34 37 00 00 33 f2 00 00 33 e4 00 00 33 df 00 00 3d f9 00 00 37 b2 00 00 34 48 00 00 33 f8 00 00 33 e6 00 00 33 e3 00 00 41 15 00 00 38 c2 00 00 34 73 00 00 34 00 00 00 33 eb 00 00 33 e7 00 00 41 15 00 00 38 c2 00 00 34 73 00 00 34 00 00 00 33 eb 00 00 33 e7 00 00 41 15 00 00 38 c2 00 00 34 73 00 00 34 00 00 00 33 eb 00 00 33 e7];
			};

			qcom,pc-temp-y4-lut {
				qcom,lut-col-legend = <0xfffffff6 0 10 25 40 50>;
				qcom,lut-row-legend = <10000 9800 9600 9400 9200 9000 8800 8600
				                       8400 8200 8000 7800 7600 7400 7200 7000
				                       6800 6600 6400 6200 6000 5800 5600 5400
				                       5200 5000 4800 4600 4400 4200 4000 3800
				                       3600 3400 3200 3000 2800 2600 2400 2200
				                       2000 1800 1600 1400 1200 1000 900 800
				                       700 600 500 400 300 200 100 0>;
				qcom,lut-data = [00 00 46 58 00 00 42 67 00 00 41 4e 00 00 40 74 00 00 40 4c 00 00 40 48 00 00 46 98 00 00 42 a9 00 00 41 4f 00 00 40 71 00 00 40 4b 00 00 40 46 00 00 46 bf 00 00 42 d5 00 00 41 4d 00 00 40 6d 00 00 40 49 00 00 40 44 00 00 46 d3 00 00 42 ef 00 00 41 4a 00 00 40 69 00 00 40 47 00 00 40 43 00 00 46 da 00 00 42 fc 00 00 41 45 00 00 40 66 00 00 40 45 00 00 40 41 00 00 46 db 00 00 43 00 00 00 41 3f 00 00 40 65 00 00 40 45 00 00 40 40 00 00 46 6d 00 00 42 f1 00 00 41 35 00 00 40 66 00 00 40 44 00 00 40 40 00 00 45 c7 00 00 42 d8 00 00 41 2b 00 00 40 66 00 00 40 44 00 00 40 3f 00 00 45 e8 00 00 42 c9 00 00 41 29 00 00 40 68 00 00 40 44 00 00 40 40 00 00 47 3b 00 00 42 bb 00 00 41 28 00 00 40 6a 00 00 40 46 00 00 40 41 00 00 48 4c 00 00 42 b5 00 00 41 28 00 00 40 6c 00 00 40 47 00 00 40 42 00 00 48 bb 00 00 42 d7 00 00 41 2b 00 00 40 70 00 00 40 49 00 00 40 43 00 00 49 0c 00 00 43 1c 00 00 41 31 00 00 40 75 00 00 40 4d 00 00 40 44 00 00 48 af 00 00 43 6c 00 00 41 48 00 00 40 7d 00 00 40 52 00 00 40 45 00 00 46 bb 00 00 43 e8 00 00 41 92 00 00 40 8a 00 00 40 59 00 00 40 49 00 00 45 66 00 00 44 26 00 00 41 ce 00 00 40 9a 00 00 40 61 00 00 40 4e 00 00 45 36 00 00 43 e3 00 00 41 f3 00 00 40 aa 00 00 40 67 00 00 40 54 00 00 45 17 00 00 43 6b 00 00 42 0c 00 00 40 be 00 00 40 70 00 00 40 5b 00 00 44 dd 00 00 43 16 00 00 42 09 00 00 40 e5 00 00 40 84 00 00 40 6a 00 00 44 7e 00 00 42 d4 00 00 41 f0 00 00 41 23 00 00 40 aa 00 00 40 84 00 00 43 ff 00 00 42 92 00 00 41 c9 00 00 41 39 00 00 40 b8 00 00 40 8e 00 00 43 07 00 00 42 43 00 00 41 6a 00 00 40 f4 00 00 40 97 00 00 40 79 00 00 41 fb 00 00 41 f9 00 00 41 04 00 00 40 9e 00 00 40 6c 00 00 40 5c 00 00 41 a6 00 00 41 cd 00 00 40 df 00 00 40 7b 00 00 40 59 00 00 40 4f 00 00 41 82 00 00 41 b2 00 00 40 cb 00 00 40 64 00 00 40 4d 00 00 40 46 00 00 41 73 00 00 41 92 00 00 40 c4 00 00 40 5e 00 00 40 49 00 00 40 44 00 00 41 71 00 00 41 57 00 00 40 c2 00 00 40 5f 00 00 40 49 00 00 40 44 00 00 41 71 00 00 41 21 00 00 40 c2 00 00 40 60 00 00 40 49 00 00 40 44 00 00 41 74 00 00 41 1d 00 00 40 c3 00 00 40 63 00 00 40 4b 00 00 40 45 00 00 41 7b 00 00 41 2d 00 00 40 c5 00 00 40 6a 00 00 40 4e 00 00 40 47 00 00 41 83 00 00 41 39 00 00 40 c5 00 00 40 71 00 00 40 53 00 00 40 4a 00 00 41 8f 00 00 41 41 00 00 40 ae 00 00 40 7a 00 00 40 59 00 00 40 50 00 00 41 9d 00 00 41 4d 00 00 40 97 00 00 40 80 00 00 40 61 00 00 40 56 00 00 41 ad 00 00 41 5c 00 00 40 9a 00 00 40 83 00 00 40 68 00 00 40 5b 00 00 41 bf 00 00 41 71 00 00 40 a8 00 00 40 85 00 00 40 6f 00 00 40 5f 00 00 41 ce 00 00 41 81 00 00 40 b8 00 00 40 83 00 00 40 6f 00 00 40 5f 00 00 41 da 00 00 41 8d 00 00 40 cb 00 00 40 6d 00 00 40 5a 00 00 40 51 00 00 41 e5 00 00 41 97 00 00 40 d9 00 00 40 59 00 00 40 46 00 00 40 43 00 00 41 ed 00 00 41 9a 00 00 40 d8 00 00 40 56 00 00 40 42 00 00 40 43 00 00 41 f3 00 00 41 98 00 00 40 d7 00 00 40 54 00 00 40 41 00 00 40 44 00 00 41 f5 00 00 41 94 00 00 40 d7 00 00 40 55 00 00 40 40 00 00 40 44 00 00 41 ec 00 00 41 82 00 00 40 e0 00 00 40 5a 00 00 40 41 00 00 40 43 00 00 41 e1 00 00 41 75 00 00 40 ea 00 00 40 5f 00 00 40 40 00 00 40 40 00 00 41 dc 00 00 41 75 00 00 40 f4 00 00 40 61 00 00 40 3a 00 00 40 33 00 00 41 ef 00 00 41 79 00 00 41 05 00 00 40 64 00 00 40 3c 00 00 40 33 00 00 41 fb 00 00 41 95 00 00 41 0c 00 00 40 72 00 00 40 47 00 00 40 45 00 00 42 2f 00 00 41 bb 00 00 41 2a 00 00 40 7f 00 00 40 5b 00 00 40 71 00 00 42 76 00 00 41 f1 00 00 41 5d 00 00 40 99 00 00 40 98 00 00 40 b2 00 00 42 b9 00 00 42 50 00 00 41 a2 00 00 40 ce 00 00 40 ad 00 00 40 92 00 00 42 c1 00 00 42 7c 00 00 41 a0 00 00 40 b3 00 00 40 5e 00 00 40 53 00 00 42 97 00 00 42 5f 00 00 41 a1 00 00 40 aa 00 00 40 5d 00 00 40 55 00 00 42 92 00 00 42 6e 00 00 41 c2 00 00 40 c8 00 00 40 74 00 00 40 68 00 00 42 d1 00 00 42 ba 00 00 42 07 00 00 41 09 00 00 40 a9 00 00 40 a0 00 00 44 93 00 00 43 51 00 00 42 cc 00 00 41 bc 00 00 41 7f 00 00 41 4e 00 00 44 93 00 00 43 51 00 00 42 cc 00 00 41 bc 00 00 41 7f 00 00 41 4e 00 00 44 93 00 00 43 51 00 00 42 cc 00 00 41 bc 00 00 41 7f 00 00 41 4e];
			};

			qcom,pc-temp-y5-lut {
				qcom,lut-col-legend = <0xfffffff6 0 10 25 40 50>;
				qcom,lut-row-legend = <10000 9800 9600 9400 9200 9000 8800 8600
				                       8400 8200 8000 7800 7600 7400 7200 7000
				                       6800 6600 6400 6200 6000 5800 5600 5400
				                       5200 5000 4800 4600 4400 4200 4000 3800
				                       3600 3400 3200 3000 2800 2600 2400 2200
				                       2000 1800 1600 1400 1200 1000 900 800
				                       700 600 500 400 300 200 100 0>;
				qcom,lut-data = [00 00 2d cf 00 00 2e a6 00 00 34 c2 00 00 3f 88 00 00 44 4d 00 00 35 af 00 00 2b b3 00 00 2f 95 00 00 36 0a 00 00 3f b0 00 00 45 31 00 00 3c 53 00 00 2a c4 00 00 30 98 00 00 37 4a 00 00 3f 1a 00 00 46 17 00 00 42 49 00 00 2a c2 00 00 31 91 00 00 38 67 00 00 3e 11 00 00 46 de 00 00 47 3e 00 00 2b 6f 00 00 32 61 00 00 39 45 00 00 3c dc 00 00 47 65 00 00 4a dc 00 00 2c 8b 00 00 32 eb 00 00 39 c8 00 00 3b c4 00 00 47 8b 00 00 4c cd 00 00 30 b1 00 00 33 2c 00 00 3a 07 00 00 3a 3f 00 00 47 49 00 00 4d 1b 00 00 35 fe 00 00 33 5e 00 00 3a 10 00 00 38 b6 00 00 46 c1 00 00 4c 61 00 00 35 66 00 00 33 f5 00 00 39 9a 00 00 38 3b 00 00 45 cb 00 00 4a a2 00 00 2d af 00 00 35 92 00 00 38 54 00 00 38 05 00 00 43 d1 00 00 47 29 00 00 28 de 00 00 36 86 00 00 37 10 00 00 37 f6 00 00 41 d5 00 00 44 e7 00 00 2c ed 00 00 33 3a 00 00 36 27 00 00 38 aa 00 00 40 16 00 00 44 bc 00 00 33 a3 00 00 2e 59 00 00 35 38 00 00 39 82 00 00 3e 49 00 00 44 cb 00 00 36 3c 00 00 2e 2f 00 00 33 de 00 00 38 a2 00 00 3c 4b 00 00 43 8f 00 00 36 18 00 00 31 e6 00 00 31 fd 00 00 35 7d 00 00 39 f2 00 00 40 97 00 00 35 7b 00 00 35 b4 00 00 31 2d 00 00 33 fd 00 00 38 86 00 00 3d e5 00 00 33 6f 00 00 38 da 00 00 31 cf 00 00 34 16 00 00 37 bf 00 00 3b 27 00 00 31 2a 00 00 3b 5b 00 00 33 33 00 00 34 4e 00 00 37 3e 00 00 38 ee 00 00 32 dc 00 00 3b 9a 00 00 36 4c 00 00 34 fc 00 00 37 48 00 00 38 a8 00 00 38 4d 00 00 3a b3 00 00 3c a3 00 00 36 f4 00 00 37 ae 00 00 39 27 00 00 3c af 00 00 3a 21 00 00 3f d6 00 00 39 83 00 00 38 6e 00 00 3a 1c 00 00 3c d7 00 00 3a 4b 00 00 40 3c 00 00 3e 29 00 00 3b 30 00 00 3d ab 00 00 3a d5 00 00 3a a6 00 00 40 5e 00 00 42 0f 00 00 3f 25 00 00 42 03 00 00 38 03 00 00 3b 5d 00 00 40 32 00 00 42 23 00 00 43 31 00 00 44 43 00 00 30 2e 00 00 3d 0b 00 00 3f d7 00 00 41 6a 00 00 47 9b 00 00 45 ee 00 00 2c 32 00 00 3e 6a 00 00 3f 8c 00 00 41 1b 00 00 49 67 00 00 46 bd 00 00 2c 87 00 00 3c 91 00 00 3e e4 00 00 40 c5 00 00 49 58 00 00 47 04 00 00 2c f8 00 00 38 b8 00 00 3e 3e 00 00 40 95 00 00 48 b7 00 00 46 f9 00 00 2d 05 00 00 35 a9 00 00 3e 9c 00 00 41 5a 00 00 46 ff 00 00 46 85 00 00 2d 1e 00 00 2f 0d 00 00 3f fc 00 00 42 ba 00 00 43 bc 00 00 45 c2 00 00 2d 44 00 00 2c 58 00 00 40 b5 00 00 43 23 00 00 41 49 00 00 44 9d 00 00 2d c6 00 00 2c b5 00 00 3f fe 00 00 42 a4 00 00 3f 46 00 00 41 ae 00 00 2e 59 00 00 2d 1e 00 00 3f 20 00 00 42 30 00 00 3e 0b 00 00 3f 37 00 00 2e 84 00 00 2d 75 00 00 3f 46 00 00 43 66 00 00 3f f7 00 00 3f c3 00 00 2e cc 00 00 2d d9 00 00 3f c7 00 00 46 22 00 00 45 19 00 00 42 35 00 00 2f 2b 00 00 2e 2a 00 00 40 27 00 00 46 e8 00 00 48 49 00 00 45 67 00 00 30 86 00 00 2e 8b 00 00 40 6f 00 00 46 3e 00 00 4a 2b 00 00 4b 28 00 00 31 fa 00 00 2f 27 00 00 40 9c 00 00 45 46 00 00 4b 67 00 00 51 13 00 00 32 2b 00 00 30 2e 00 00 40 3c 00 00 44 11 00 00 4c d5 00 00 55 45 00 00 32 0c 00 00 32 18 00 00 3e f4 00 00 42 7c 00 00 4f 28 00 00 58 c3 00 00 31 c4 00 00 33 1e 00 00 3d 2f 00 00 41 0e 00 00 4f ef 00 00 59 5f 00 00 30 44 00 00 31 c5 00 00 3a 0e 00 00 3f 2b 00 00 50 3d 00 00 57 b1 00 00 2e 6a 00 00 2f e8 00 00 38 21 00 00 3e a2 00 00 50 92 00 00 58 b7 00 00 2d 32 00 00 2e ad 00 00 37 48 00 00 3f 17 00 00 52 1c 00 00 61 03 00 00 2c df 00 00 2e af 00 00 36 b6 00 00 3d c8 00 00 49 2e 00 00 50 c2 00 00 2d 8e 00 00 2e 7f 00 00 36 77 00 00 3e 83 00 00 45 8d 00 00 4e d5 00 00 2d 87 00 00 2f 45 00 00 35 72 00 00 3c 42 00 00 42 c6 00 00 44 af 00 00 2e 40 00 00 30 90 00 00 35 e9 00 00 3e 8f 00 00 3f c4 00 00 3a 9e 00 00 30 bc 00 00 32 94 00 00 37 4b 00 00 3c 46 00 00 3a 32 00 00 39 02 00 00 31 d0 00 00 33 5f 00 00 37 f3 00 00 3f 80 00 00 45 7f 00 00 43 78 00 00 2f 31 00 00 33 11 00 00 37 cd 00 00 41 e5 00 00 44 dd 00 00 44 d9 00 00 2d d6 00 00 32 3a 00 00 37 77 00 00 41 43 00 00 4a de 00 00 45 e1 00 00 2d fa 00 00 31 17 00 00 36 79 00 00 42 f9 00 00 47 8d 00 00 47 fd 00 00 2e c8 00 00 2f d4 00 00 3b 77 00 00 42 3f 00 00 45 78 00 00 43 d7 00 00 2e c8 00 00 2f d4 00 00 3b 77 00 00 42 3f 00 00 45 78 00 00 43 d7 00 00 2e c8 00 00 2f d4 00 00 3b 77 00 00 42 3f 00 00 45 78 00 00 43 d7];
			};

			qcom,pc-temp-y6-lut {
				qcom,lut-col-legend = <0xfffffff6 0 10 25 40 50>;
				qcom,lut-row-legend = <10000 9800 9600 9400 9200 9000 8800 8600
				                       8400 8200 8000 7800 7600 7400 7200 7000
				                       6800 6600 6400 6200 6000 5800 5600 5400
				                       5200 5000 4800 4600 4400 4200 4000 3800
				                       3600 3400 3200 3000 2800 2600 2400 2200
				                       2000 1800 1600 1400 1200 1000 900 800
				                       700 600 500 400 300 200 100 0>;
				qcom,lut-data = [00 00 19 97 00 00 15 e0 00 00 14 64 00 00 13 7e 00 00 13 4f 00 00 13 42 00 00 19 86 00 00 15 e5 00 00 14 60 00 00 13 7c 00 00 13 4e 00 00 13 43 00 00 19 6f 00 00 15 e5 00 00 14 5b 00 00 13 7a 00 00 13 4e 00 00 13 43 00 00 19 58 00 00 15 e1 00 00 14 55 00 00 13 78 00 00 13 4e 00 00 13 43 00 00 19 46 00 00 15 da 00 00 14 4f 00 00 13 77 00 00 13 4e 00 00 13 44 00 00 19 3d 00 00 15 d0 00 00 14 49 00 00 13 76 00 00 13 4e 00 00 13 44 00 00 19 3c 00 00 15 c2 00 00 14 42 00 00 13 75 00 00 13 4e 00 00 13 44 00 00 19 3d 00 00 15 b2 00 00 14 3b 00 00 13 74 00 00 13 4e 00 00 13 44 00 00 19 32 00 00 15 a9 00 00 14 36 00 00 13 75 00 00 13 4e 00 00 13 44 00 00 19 03 00 00 15 a2 00 00 14 31 00 00 13 75 00 00 13 4e 00 00 13 45 00 00 18 e7 00 00 15 9f 00 00 14 2e 00 00 13 76 00 00 13 4f 00 00 13 45 00 00 19 21 00 00 15 a0 00 00 14 2d 00 00 13 78 00 00 13 4f 00 00 13 45 00 00 19 75 00 00 15 a3 00 00 14 2c 00 00 13 7b 00 00 13 51 00 00 13 46 00 00 19 68 00 00 15 ac 00 00 14 31 00 00 13 7d 00 00 13 52 00 00 13 47 00 00 18 da 00 00 15 c9 00 00 14 47 00 00 13 81 00 00 13 55 00 00 13 48 00 00 18 72 00 00 15 d9 00 00 14 56 00 00 13 86 00 00 13 57 00 00 13 4a 00 00 18 57 00 00 15 c8 00 00 14 5a 00 00 13 8b 00 00 13 5a 00 00 13 4b 00 00 18 44 00 00 15 a7 00 00 14 5c 00 00 13 91 00 00 13 5c 00 00 13 4e 00 00 18 41 00 00 15 8a 00 00 14 5b 00 00 13 9d 00 00 13 62 00 00 13 52 00 00 18 3d 00 00 15 6e 00 00 14 53 00 00 13 b0 00 00 13 6e 00 00 13 5b 00 00 18 37 00 00 15 53 00 00 14 46 00 00 13 b6 00 00 13 72 00 00 13 5e 00 00 18 0c 00 00 15 37 00 00 14 27 00 00 13 9f 00 00 13 66 00 00 13 56 00 00 17 d5 00 00 15 1f 00 00 14 05 00 00 13 82 00 00 13 57 00 00 13 4b 00 00 17 d0 00 00 15 15 00 00 13 f9 00 00 13 76 00 00 13 51 00 00 13 46 00 00 17 e7 00 00 15 11 00 00 13 f3 00 00 13 6e 00 00 13 4d 00 00 13 43 00 00 18 02 00 00 15 0b 00 00 13 f1 00 00 13 6c 00 00 13 4c 00 00 13 42 00 00 18 2a 00 00 14 fd 00 00 13 f1 00 00 13 6d 00 00 13 4c 00 00 13 42 00 00 18 5d 00 00 14 ef 00 00 13 f2 00 00 13 6e 00 00 13 4c 00 00 13 43 00 00 18 8d 00 00 14 ef 00 00 13 f4 00 00 13 6f 00 00 13 4c 00 00 13 43 00 00 18 bf 00 00 14 fe 00 00 13 f8 00 00 13 72 00 00 13 4d 00 00 13 44 00 00 18 f2 00 00 15 12 00 00 13 f9 00 00 13 75 00 00 13 4e 00 00 13 45 00 00 19 26 00 00 15 2a 00 00 13 f5 00 00 13 78 00 00 13 50 00 00 13 46 00 00 19 5b 00 00 15 48 00 00 13 f2 00 00 13 7a 00 00 13 52 00 00 13 48 00 00 19 92 00 00 15 66 00 00 13 f5 00 00 13 7c 00 00 13 55 00 00 13 4a 00 00 19 cb 00 00 15 88 00 00 14 00 00 00 13 7d 00 00 13 58 00 00 13 4b 00 00 1a 09 00 00 15 ab 00 00 14 0d 00 00 13 7d 00 00 13 58 00 00 13 4b 00 00 1a 4c 00 00 15 cf 00 00 14 19 00 00 13 77 00 00 13 52 00 00 13 48 00 00 1a 93 00 00 15 f5 00 00 14 26 00 00 13 72 00 00 13 4c 00 00 13 44 00 00 1a dc 00 00 16 1e 00 00 14 2f 00 00 13 72 00 00 13 4c 00 00 13 44 00 00 1b 26 00 00 16 4c 00 00 14 38 00 00 13 72 00 00 13 4c 00 00 13 45 00 00 1b 6e 00 00 16 7a 00 00 14 42 00 00 13 73 00 00 13 4c 00 00 13 45 00 00 1b b1 00 00 16 a7 00 00 14 51 00 00 13 76 00 00 13 4e 00 00 13 46 00 00 1b f5 00 00 16 da 00 00 14 63 00 00 13 79 00 00 13 4e 00 00 13 45 00 00 1c 43 00 00 17 1b 00 00 14 78 00 00 13 7b 00 00 13 4b 00 00 13 41 00 00 1c a2 00 00 17 73 00 00 14 98 00 00 13 7f 00 00 13 4d 00 00 13 42 00 00 1c 9e 00 00 17 9d 00 00 14 9f 00 00 13 86 00 00 13 52 00 00 13 49 00 00 1c e3 00 00 17 d8 00 00 14 b8 00 00 13 8b 00 00 13 58 00 00 13 56 00 00 1d 3b 00 00 18 1d 00 00 14 dd 00 00 13 96 00 00 13 6d 00 00 13 6a 00 00 1d 99 00 00 18 75 00 00 15 09 00 00 13 a8 00 00 13 72 00 00 13 60 00 00 1d e8 00 00 18 bb 00 00 15 15 00 00 13 a0 00 00 13 5a 00 00 13 4d 00 00 1e 2f 00 00 18 f8 00 00 15 29 00 00 13 9f 00 00 13 5b 00 00 13 4f 00 00 1e c1 00 00 19 75 00 00 15 5c 00 00 13 ab 00 00 13 65 00 00 13 56 00 00 1f 8e 00 00 1a 2e 00 00 15 a3 00 00 13 c4 00 00 13 76 00 00 13 6a 00 00 22 95 00 00 1b 2a 00 00 16 31 00 00 14 00 00 00 13 b7 00 00 13 9f 00 00 22 95 00 00 1b 2a 00 00 16 31 00 00 14 00 00 00 13 b7 00 00 13 9f 00 00 22 95 00 00 1b 2a 00 00 16 31 00 00 14 00 00 00 13 b7 00 00 13 9f];
			};
		};
	};
};

&tlmm {
	smb_int_default: smb_int_default {
		mux {
			pins = "gpio105";
			function = "gpio";
		};

		config {
			pins = "gpio105";
			bias-pull-up;
			input-enable;
		};
	};
};

&qupv3_se1_i2c {
	status = "ok";

	smb1394: qcom,smb1394@34 {
		compatible = "qcom,i2c-pmic";
		reg = <0x34>;
		#address-cells = <1>;
		#size-cells = <0>;
		interrupt-controller;
		#interrupt-cells = <3>;
		qcom,periph-map = <6 38 39>;
		status = "ok";
		pinctrl-names = "default";
		pinctrl-0 = <&pm7250b_smb_int_default>;
		interrupt-parent = <&spmi_bus>;
		interrupt-names = "smb1394";
		interrupts = <2 197 0 8>;
		qcom,enable-toggle-stat;

		smb1394_div2_cp_primary: qcom,div2_cp_pry {
			compatible = "qcom,smb1394-div2-cp-primary";
			#io-channel-cells = <1>;
			interrupts = <38 1 1 38 3 1
			              38 5 1 38 7 1
			              39 5 1 39 6 1
			              39 7 1>;
			interrupt-names = "temp-shdwn", "div2-irev", "usbin-uv", "usbin-ov", "div2-ilim", "div2-win-uv", "div2-win-ov";
			qcom,div2-cp-min-ilim-ua = <1000000>;
			status = "ok";
			io-channels = <&pm7250b_vadc 14>;
			io-channel-names = "die_temp";
			qcom,parallel-input-mode = <1>;
			qcom,parallel-output-mode = <2>;
		};
	};
};

&usb0 {
	extcon = <&pm7250b_pdphy &pm7250b_charger &eud>;
};

&thermal_zones {
	quiet-therm {
		cooling-maps {
			quiet_batt_cdev1 {
				trip = <&quiet_batt_trip0>;
				cooling-device = <&pm7250b_charger 8 8>;
			};

			quiet_batt_cdev2 {
				trip = <&quiet_batt_trip1>;
				cooling-device = <&pm7250b_charger 12 12>;
			};

			quiet_batt_cdev3 {
				trip = <&quiet_batt_trip2>;
				cooling-device = <&pm7250b_charger 14 14>;
			};

			quiet_batt_cdev4 {
				trip = <&quiet_batt_trip3>;
				cooling-device = <&pm7250b_charger 16 16>;
			};
		};
	};

	pm7250b-tz {
		cooling-maps {
			trip0_bat {
				cooling-device = <&pm7250b_charger 15 15>;
			};

			trip1_bat {
				cooling-device = <&pm7250b_charger 16 16>;
			};
		};
	};
};
